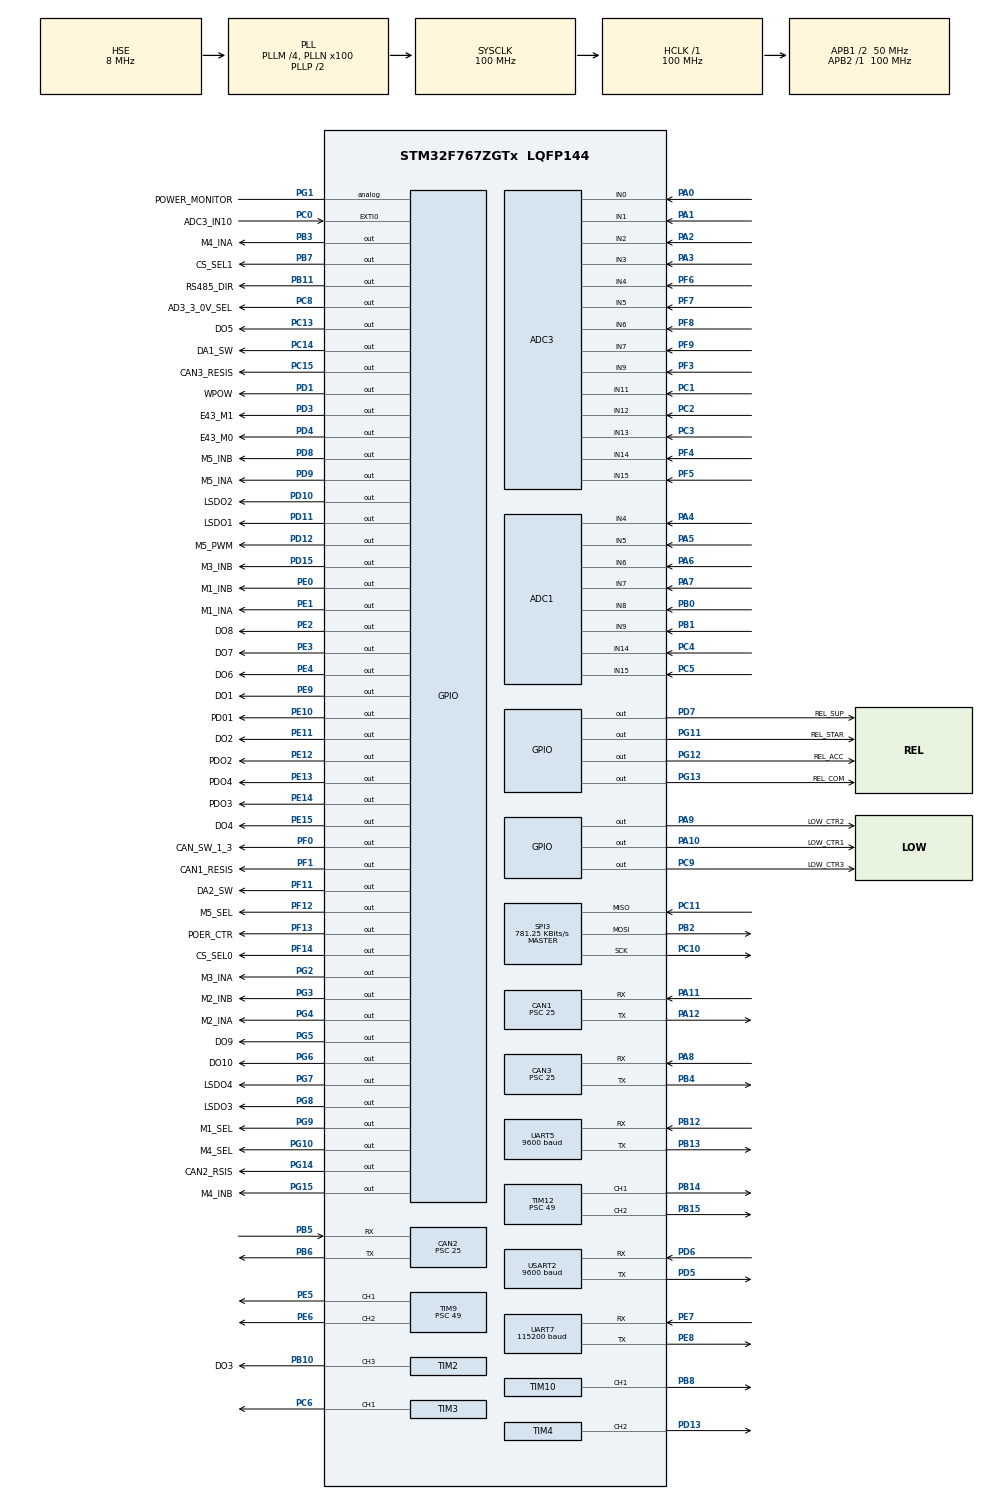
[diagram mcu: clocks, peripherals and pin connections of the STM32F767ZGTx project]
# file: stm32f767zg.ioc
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ADC1.Channel-0\#ChannelRegularConversion=ADC_CHANNEL_4
ADC1.Channel-1\#ChannelRegularConversion=ADC_CHANNEL_5
ADC1.Channel-10\#ChannelRegularConversion=ADC_CHANNEL_14
ADC1.Channel-11\#ChannelRegularConversion=ADC_CHANNEL_15
ADC1.Channel-12\#ChannelRegularConversion=ADC_CHANNEL_TEMPSENSOR
ADC1.Channel-13\#ChannelRegularConversion=ADC_CHANNEL_VREFINT
ADC1.Channel-6\#ChannelRegularConversion=ADC_CHANNEL_6
ADC1.Channel-7\#ChannelRegularConversion=ADC_CHANNEL_7
ADC1.Channel-8\#ChannelRegularConversion=ADC_CHANNEL_8
ADC1.Channel-9\#ChannelRegularConversion=ADC_CHANNEL_9
ADC1.ContinuousConvMode=ENABLE
ADC1.DMAContinuousRequests=ENABLE
ADC1.EOCSelection=ADC_EOC_SEQ_CONV
ADC1.InjNumberOfConversion=0
ADC1.NbrOfConversion=10
ADC1.NbrOfConversionFlag=1
ADC1.Rank-0\#ChannelRegularConversion=1
ADC1.Rank-1\#ChannelRegularConversion=2
ADC1.Rank-10\#ChannelRegularConversion=7
ADC1.Rank-11\#ChannelRegularConversion=8
ADC1.Rank-12\#ChannelRegularConversion=9
ADC1.Rank-13\#ChannelRegularConversion=10
ADC1.Rank-6\#ChannelRegularConversion=3
ADC1.Rank-7\#ChannelRegularConversion=4
ADC1.Rank-8\#ChannelRegularConversion=5
ADC1.Rank-9\#ChannelRegularConversion=6
ADC1.SamplingTime-0\#ChannelRegularConversion=ADC_SAMPLETIME_56CYCLES
ADC1.SamplingTime-1\#ChannelRegularConversion=ADC_SAMPLETIME_56CYCLES
ADC1.SamplingTime-10\#ChannelRegularConversion=ADC_SAMPLETIME_56CYCLES
ADC1.SamplingTime-11\#ChannelRegularConversion=ADC_SAMPLETIME_56CYCLES
ADC1.SamplingTime-12\#ChannelRegularConversion=ADC_SAMPLETIME_112CYCLES
ADC1.SamplingTime-13\#ChannelRegularConversion=ADC_SAMPLETIME_3CYCLES
ADC1.SamplingTime-6\#ChannelRegularConversion=ADC_SAMPLETIME_56CYCLES
ADC1.SamplingTime-7\#ChannelRegularConversion=ADC_SAMPLETIME_56CYCLES
ADC1.SamplingTime-8\#ChannelRegularConversion=ADC_SAMPLETIME_56CYCLES
ADC1.SamplingTime-9\#ChannelRegularConversion=ADC_SAMPLETIME_56CYCLES
ADC1.ScanConvMode=ADC_SCAN_ENABLE
ADC1.master=1
ADC3.Channel-0\#ChannelRegularConversion=ADC_CHANNEL_0
ADC3.Channel-1\#ChannelRegularConversion=ADC_CHANNEL_1
ADC3.Channel-10\#ChannelRegularConversion=ADC_CHANNEL_12
ADC3.Channel-11\#ChannelRegularConversion=ADC_CHANNEL_13
ADC3.Channel-12\#ChannelRegularConversion=ADC_CHANNEL_14
ADC3.Channel-13\#ChannelRegularConversion=ADC_CHANNEL_15
ADC3.Channel-14\#ChannelRegularConversion=ADC_CHANNEL_7
ADC3.Channel-2\#ChannelRegularConversion=ADC_CHANNEL_2
ADC3.Channel-3\#ChannelRegularConversion=ADC_CHANNEL_3
ADC3.Channel-4\#ChannelRegularConversion=ADC_CHANNEL_4
ADC3.Channel-5\#ChannelRegularConversion=ADC_CHANNEL_5
ADC3.Channel-6\#ChannelRegularConversion=ADC_CHANNEL_6
ADC3.Channel-7\#ChannelRegularConversion=ADC_CHANNEL_9
ADC3.Channel-8\#ChannelRegularConversion=ADC_CHANNEL_9
ADC3.Channel-9\#ChannelRegularConversion=ADC_CHANNEL_11
ADC3.ContinuousConvMode=ENABLE
ADC3.DMAContinuousRequests=ENABLE
ADC3.NbrOfConversion=15
ADC3.NbrOfConversionFlag=1
ADC3.Rank-0\#ChannelRegularConversion=1
ADC3.Rank-1\#ChannelRegularConversion=2
ADC3.Rank-10\#ChannelRegularConversion=11
ADC3.Rank-11\#ChannelRegularConversion=12
ADC3.Rank-12\#ChannelRegularConversion=13
ADC3.Rank-13\#ChannelRegularConversion=14
ADC3.Rank-14\#ChannelRegularConversion=15
ADC3.Rank-2\#ChannelRegularConversion=3
ADC3.Rank-3\#ChannelRegularConversion=4
ADC3.Rank-4\#ChannelRegularConversion=5
ADC3.Rank-5\#ChannelRegularConversion=6
ADC3.Rank-6\#ChannelRegularConversion=7
ADC3.Rank-7\#ChannelRegularConversion=8
ADC3.Rank-8\#ChannelRegularConversion=9
ADC3.Rank-9\#ChannelRegularConversion=10
ADC3.SamplingTime-0\#ChannelRegularConversion=ADC_SAMPLETIME_56CYCLES
ADC3.SamplingTime-1\#ChannelRegularConversion=ADC_SAMPLETIME_56CYCLES
ADC3.SamplingTime-10\#ChannelRegularConversion=ADC_SAMPLETIME_56CYCLES
ADC3.SamplingTime-11\#ChannelRegularConversion=ADC_SAMPLETIME_56CYCLES
ADC3.SamplingTime-12\#ChannelRegularConversion=ADC_SAMPLETIME_56CYCLES
ADC3.SamplingTime-13\#ChannelRegularConversion=ADC_SAMPLETIME_56CYCLES
ADC3.SamplingTime-14\#ChannelRegularConversion=ADC_SAMPLETIME_56CYCLES
ADC3.SamplingTime-2\#ChannelRegularConversion=ADC_SAMPLETIME_56CYCLES
ADC3.SamplingTime-3\#ChannelRegularConversion=ADC_SAMPLETIME_56CYCLES
ADC3.SamplingTime-4\#ChannelRegularConversion=ADC_SAMPLETIME_56CYCLES
ADC3.SamplingTime-5\#ChannelRegularConversion=ADC_SAMPLETIME_56CYCLES
ADC3.SamplingTime-6\#ChannelRegularConversion=ADC_SAMPLETIME_56CYCLES
ADC3.SamplingTime-7\#ChannelRegularConversion=ADC_SAMPLETIME_56CYCLES
ADC3.SamplingTime-8\#ChannelRegularConversion=ADC_SAMPLETIME_15CYCLES
ADC3.SamplingTime-9\#ChannelRegularConversion=ADC_SAMPLETIME_56CYCLES
ADC3.ScanConvMode=ADC_SCAN_ENABLE
CAN1.ABOM=DISABLE
CAN1.AWUM=DISABLE
CAN1.BS1=CAN_BS1_4TQ
CAN1.BS2=CAN_BS2_3TQ
CAN1.CalculateBaudRate=250000
CAN1.CalculateTimeBit=4000
CAN1.CalculateTimeQuantum=500.0
CAN1.Mode=CAN_MODE_NORMAL
CAN1.NART=DISABLE
CAN1.Prescaler=25
CAN1.RFLM=DISABLE
CAN1.SJW=CAN_SJW_1TQ
CAN1.TTCM=DISABLE
CAN1.TXFP=DISABLE
CAN2.ABOM=DISABLE
CAN2.AWUM=DISABLE
CAN2.BS1=CAN_BS1_4TQ
CAN2.BS2=CAN_BS2_3TQ
CAN2.CalculateBaudRate=250000
CAN2.CalculateTimeBit=4000
CAN2.CalculateTimeQuantum=500.0
CAN2.Mode=CAN_MODE_NORMAL
CAN2.NART=DISABLE
CAN2.Prescaler=25
CAN2.RFLM=DISABLE
CAN2.SJW=CAN_SJW_1TQ
CAN2.TTCM=DISABLE
CAN2.TXFP=DISABLE
CAN3.ABOM=DISABLE
CAN3.AWUM=DISABLE
CAN3.BS1=CAN_BS1_4TQ
CAN3.BS2=CAN_BS2_3TQ
CAN3.CalculateBaudRate=250000
CAN3.CalculateTimeBit=4000
CAN3.CalculateTimeQuantum=500.0
CAN3.Mode=CAN_MODE_NORMAL
CAN3.NART=DISABLE
CAN3.Prescaler=25
CAN3.RFLM=DISABLE
CAN3.SJW=CAN_SJW_1TQ
CAN3.TTCM=DISABLE
CAN3.TXFP=DISABLE
CORTEX_M7.ART_ACCLERATOR_ENABLE=0
CORTEX_M7.CPU_DCache=Enabled
CORTEX_M7.CPU_ICache=Enabled
CORTEX_M7.FlashInterface=AXI_Enabled
CORTEX_M7.MPU_Control=__NULL
CORTEX_M7.PREFETCH_ENABLE=0
Dma.ADC1.0.Direction=DMA_PERIPH_TO_MEMORY
Dma.ADC1.0.FIFOMode=DMA_FIFOMODE_DISABLE
Dma.ADC1.0.Instance=DMA2_Stream0
Dma.ADC1.0.MemDataAlignment=DMA_MDATAALIGN_WORD
Dma.ADC1.0.MemInc=DMA_MINC_ENABLE
Dma.ADC1.0.Mode=DMA_CIRCULAR
Dma.ADC1.0.PeriphDataAlignment=DMA_PDATAALIGN_WORD
Dma.ADC1.0.PeriphInc=DMA_PINC_DISABLE
Dma.ADC1.0.Priority=DMA_PRIORITY_LOW
Dma.ADC3.1.Direction=DMA_PERIPH_TO_MEMORY
Dma.ADC3.1.FIFOMode=DMA_FIFOMODE_DISABLE
Dma.ADC3.1.Instance=DMA2_Stream1
Dma.ADC3.1.MemDataAlignment=DMA_MDATAALIGN_WORD
Dma.ADC3.1.MemInc=DMA_MINC_ENABLE
Dma.ADC3.1.Mode=DMA_CIRCULAR
Dma.ADC3.1.PeriphDataAlignment=DMA_PDATAALIGN_WORD
Dma.ADC3.1.PeriphInc=DMA_PINC_DISABLE
Dma.ADC3.1.Priority=DMA_PRIORITY_LOW
Dma.Request0=ADC1
Dma.Request1=ADC3
FREERTOS.CountingSemaphores01=myCountingSemMoter1,1,Dynamic,NULL;myCountingSemMoter2,1,Dynamic,NULL;myCountingSemMoter3,1,Dynamic,NULL;myCountingSemMoter4,1,Dynamic,NULL;myCountingSemMoter5,1,Dynamic,NULL;myCountingSemEngine,1,Dynamic,NULL;myCountingSemDO,1,Dynamic,NULL;myCountingSemPend1,1,Dynamic,NULL;myCountingSemElecAccelerator,1,Dynamic,NULL;myCountingSemTube,1,Dynamic,NULL;myCountingSemTurn,1,Dynamic,NULL;myCountingSemAutoTurn,1,Dynamic,NULL
FREERTOS.HEAP_NUMBER=4
FREERTOS.INCLUDE_eTaskGetState=1
FREERTOS.INCLUDE_pcTaskGetTaskName=0
FREERTOS.INCLUDE_uxTaskGetStackHighWaterMark=1
FREERTOS.INCLUDE_uxTaskGetStackHighWaterMark2=0
FREERTOS.INCLUDE_uxTaskPriorityGet=1
FREERTOS.INCLUDE_vTaskCleanUpResources=0
FREERTOS.INCLUDE_vTaskDelay=1
FREERTOS.INCLUDE_vTaskDelayUntil=1
FREERTOS.INCLUDE_vTaskDelete=1
FREERTOS.INCLUDE_vTaskPrioritySet=1
FREERTOS.INCLUDE_vTaskSuspend=1
FREERTOS.INCLUDE_xEventGroupSetBitFromISR=0
FREERTOS.INCLUDE_xQueueGetMutexHolder=1
FREERTOS.INCLUDE_xSemaphoreGetMutexHolder=0
FREERTOS.INCLUDE_xTaskAbortDelay=0
FREERTOS.INCLUDE_xTaskGetCurrentTaskHandle=0
FREERTOS.INCLUDE_xTaskGetHandle=0
FREERTOS.INCLUDE_xTaskGetSchedulerState=1
FREERTOS.INCLUDE_xTaskResumeFromISR=1
FREERTOS.INCLUDE_xTimerPendFunctionCall=1
FREERTOS.Queues01=myQueueCan2Rev,5,12,1,Dynamic,NULL,NULL;myQueueCan1Rev,5,12,1,Dynamic,NULL,NULL;myQueueCan3Rev,5,12,1,Dynamic,NULL,NULL;myQueueUart7Rec,2,30,1,Dynamic,NULL,NULL;myQueueUart2Spi3Rec,6,10,1,Dynamic,NULL,NULL
FREERTOS.Tasks01=defaultTask,8,128,StartDefaultTask,Default,NULL,Dynamic,NULL,NULL;myTask02,47,128,StartTask02,Default,NULL,Dynamic,NULL,NULL;myTask03,46,128,StartTask03,Default,NULL,Dynamic,NULL,NULL;myTask04,45,128,StartTask04,Default,NULL,Dynamic,NULL,NULL;myTask05,44,128,StartTask05,Default,NULL,Dynamic,NULL,NULL;myTask06,43,128,StartTask06,Default,NULL,Dynamic,NULL,NULL;myTask07,42,128,StartTask07,Default,NULL,Dynamic,NULL,NULL;myTask08,31,128,StartTask08,Default,NULL,Dynamic,NULL,NULL;myTask09,30,128,StartTask09,Default,NULL,Dynamic,NULL,NULL;myTask10,29,128,StartTask10,Default,NULL,Dynamic,NULL,NULL;myTask11,28,128,StartTask11,Default,NULL,Dynamic,NULL,NULL;myTask12,27,128,StartTask12,Default,NULL,Dynamic,NULL,NULL;myTask13,26,128,StartTask13,Default,NULL,Dynamic,NULL,NULL;myTask14,25,128,StartTask14,Default,NULL,Dynamic,NULL,NULL;myTask15,24,128,StartTask15,Default,NULL,Dynamic,NULL,NULL;myTask20,9,128,StartTask20,Default,NULL,Dynamic,NULL,NULL;myTask16,23,128,StartTask16,Default,NULL,Dynamic,NULL,NULL;myTask17,22,128,StartTask17,Default,NULL,Dynamic,NULL,NULL;myTask18,21,128,StartTask18,Default,NULL,Dynamic,NULL,NULL;myTask19,20,128,StartTask19,Default,NULL,Dynamic,NULL,NULL;myTask21,41,128,StartTask21,Default,NULL,Dynamic,NULL,NULL
FREERTOS.Timers01=myTimerCanSend,CallbackCanSend,osTimerPeriodic,Default,NULL,Dynamic,NULL;myTimerDO,CallbackDO,osTimerPeriodic,Default,NULL,Dynamic,NULL;myTimerCounter,CallbackCounter,osTimerPeriodic,Default,NULL,Dynamic,NULL
FREERTOS.configCHECK_FOR_STACK_OVERFLOW=0
FREERTOS.configENABLE_BACKWARD_COMPATIBILITY=1
FREERTOS.configENABLE_FPU=0
FREERTOS.configGENERATE_RUN_TIME_STATS=0
FREERTOS.configIDLE_SHOULD_YIELD=1
FREERTOS.configLIBRARY_LOWEST_INTERRUPT_PRIORITY=15
FREERTOS.configLIBRARY_MAX_SYSCALL_INTERRUPT_PRIORITY=5
FREERTOS.configMAX_CO_ROUTINE_PRIORITIES=2
FREERTOS.configMAX_TASK_NAME_LEN=16
FREERTOS.configMINIMAL_STACK_SIZE=128
FREERTOS.configQUEUE_REGISTRY_SIZE=8
FREERTOS.configRECORD_STACK_HIGH_ADDRESS=0
FREERTOS.configTICK_RATE_HZ=1000
FREERTOS.configTIMER_QUEUE_LENGTH=10
FREERTOS.configTIMER_TASK_PRIORITY=2
FREERTOS.configTIMER_TASK_STACK_DEPTH=256
FREERTOS.configTOTAL_HEAP_SIZE=15360
FREERTOS.configUSE_APPLICATION_TASK_TAG=0
FREERTOS.configUSE_COUNTING_SEMAPHORES=1
FREERTOS.configUSE_CO_ROUTINES=0
FREERTOS.configUSE_DAEMON_TASK_STARTUP_HOOK=0
FREERTOS.configUSE_IDLE_HOOK=0
FREERTOS.configUSE_MALLOC_FAILED_HOOK=0
FREERTOS.configUSE_MUTEXES=1
FREERTOS.configUSE_NEWLIB_REENTRANT=0
FREERTOS.configUSE_POSIX_ERRNO=0
FREERTOS.configUSE_PREEMPTION=1
FREERTOS.configUSE_RECURSIVE_MUTEXES=1
FREERTOS.configUSE_STATS_FORMATTING_FUNCTIONS=0
FREERTOS.configUSE_TASK_NOTIFICATIONS=1
FREERTOS.configUSE_TICKLESS_IDLE=0
FREERTOS.configUSE_TICK_HOOK=0
FREERTOS.configUSE_TRACE_FACILITY=1
FREERTOS.copyHeapFile=1
IWDG.Prescaler=IWDG_PRESCALER_32
IWDG.Reload=2000
IWDG.Window=2000
Mcu.Family=STM32F7
Mcu.Name=STM32F767ZGTx
Mcu.Package=LQFP144
NVIC.CAN1_RX0_IRQn=true\:6\:0\:true\:false\:true\:true\:true\:true\:true
NVIC.CAN2_RX1_IRQn=true\:7\:0\:true\:false\:true\:true\:true\:true\:true
NVIC.CAN3_RX0_IRQn=true\:8\:0\:true\:false\:true\:true\:true\:true\:true
NVIC.DMA2_Stream0_IRQn=true\:5\:0\:false\:false\:true\:true\:false\:true\:true
NVIC.DMA2_Stream1_IRQn=true\:5\:0\:false\:false\:true\:true\:false\:true\:true
NVIC.EXTI0_IRQn=true\:5\:0\:false\:false\:true\:true\:true\:true\:true
NVIC.PriorityGroup=NVIC_PRIORITYGROUP_4
NVIC.TIM8_TRG_COM_TIM14_IRQn=true\:0\:0\:false\:false\:true\:false\:false\:true\:true
NVIC.TimeBase=TIM8_TRG_COM_TIM14_IRQn
NVIC.TimeBaseIP=TIM14
NVIC.UART5_IRQn=true\:11\:0\:true\:false\:true\:true\:true\:true\:true
NVIC.UART7_IRQn=true\:15\:0\:true\:false\:true\:true\:true\:true\:true
NVIC.USART2_IRQn=true\:10\:0\:true\:false\:true\:true\:true\:true\:true
PA0/WKUP.Signal=ADCx_IN0
PA1.Signal=ADCx_IN1
PA10.GPIO_Label=LOW_CTR1
PA10.Signal=GPIO_Output
PA11.Mode=CAN_Activate
PA11.Signal=CAN1_RX
PA12.Mode=CAN_Activate
PA12.Signal=CAN1_TX
PA13.Mode=Serial_Wire
PA13.Signal=SYS_JTMS-SWDIO
PA14.Mode=Serial_Wire
PA14.Signal=SYS_JTCK-SWCLK
PA2.Signal=ADCx_IN2
PA3.Signal=ADCx_IN3
PA4.Signal=ADCx_IN4
PA5.Signal=ADCx_IN5
PA6.Signal=ADCx_IN6
PA7.Signal=ADCx_IN7
PA8.Mode=CAN_Activate
PA8.Signal=CAN3_RX
PA9.GPIO_Label=LOW_CTR2
PA9.Signal=GPIO_Output
PB0.Signal=ADCx_IN8
PB1.Signal=ADCx_IN9
PB10.GPIO_Label=DO3
PB10.Signal=S_TIM2_CH3
PB11.GPIO_Label=RS485_DIR
PB11.Signal=GPIO_Output
PB12.Mode=Asynchronous
PB12.Signal=UART5_RX
PB13.Mode=Asynchronous
PB13.Signal=UART5_TX
PB14.Signal=S_TIM12_CH1
PB15.Signal=S_TIM12_CH2
PB2.Mode=Full_Duplex_Master
PB2.Signal=SPI3_MOSI
PB3.GPIO_Label=M4_INA
PB3.Signal=GPIO_Output
PB4.Mode=CAN_Activate
PB4.Signal=CAN3_TX
PB5.Mode=CAN_Activate
PB5.Signal=CAN2_RX
PB6.Mode=CAN_Activate
PB6.Signal=CAN2_TX
PB7.GPIO_Label=CS_SEL1
PB7.Signal=GPIO_Output
PB8.Signal=S_TIM10_CH1
PC0.GPIO_Label=ADC3_IN10
PC0.Signal=GPXTI0
PC1.Signal=ADCx_IN11
PC10.Mode=Full_Duplex_Master
PC10.Signal=SPI3_SCK
PC11.Mode=Full_Duplex_Master
PC11.Signal=SPI3_MISO
PC13.GPIO_Label=DO5
PC13.Signal=GPIO_Output
PC14/OSC32_IN.GPIO_Label=DA1_SW
PC14/OSC32_IN.Signal=GPIO_Output
PC15/OSC32_OUT.GPIO_Label=CAN3_RESIS
PC15/OSC32_OUT.Signal=GPIO_Output
PC2.Signal=ADCx_IN12
PC3.Signal=ADCx_IN13
PC4.Signal=ADCx_IN14
PC5.Signal=ADCx_IN15
PC6.Signal=S_TIM3_CH1
PC8.GPIO_Label=AD3_3_0V_SEL
PC8.Signal=GPIO_Output
PC9.GPIO_Label=LOW_CTR3
PC9.Signal=GPIO_Output
PD1.GPIO_Label=WPOW
PD1.Signal=GPIO_Output
PD10.GPIO_Label=LSDO2
PD10.Signal=GPIO_Output
PD11.GPIO_Label=LSDO1
PD11.Signal=GPIO_Output
PD12.GPIO_Label=M5_PWM
PD12.Signal=GPIO_Output
PD13.Signal=S_TIM4_CH2
PD15.GPIO_Label=M3_INB
PD15.Signal=GPIO_Output
PD3.GPIO_Label=E43_M1
PD3.Signal=GPIO_Output
PD4.GPIO_Label=E43_M0
PD4.Signal=GPIO_Output
PD5.Mode=Asynchronous
PD5.Signal=USART2_TX
PD6.Mode=Asynchronous
PD6.Signal=USART2_RX
PD7.GPIO_Label=REL_SUP
PD7.Signal=GPIO_Output
PD8.GPIO_Label=M5_INB
PD8.Signal=GPIO_Output
PD9.GPIO_Label=M5_INA
PD9.Signal=GPIO_Output
PE0.GPIO_Label=M1_INB
PE0.Signal=GPIO_Output
PE1.GPIO_Label=M1_INA
PE1.Signal=GPIO_Output
PE10.GPIO_Label=PD01
PE10.Signal=GPIO_Output
PE11.GPIO_Label=DO2
PE11.Signal=GPIO_Output
PE12.GPIO_Label=PDO2
PE12.Signal=GPIO_Output
PE13.GPIO_Label=PDO4
PE13.Signal=GPIO_Output
PE14.GPIO_Label=PDO3
PE14.Signal=GPIO_Output
PE15.GPIO_Label=DO4
PE15.Signal=GPIO_Output
PE2.GPIO_Label=DO8
PE2.Signal=GPIO_Output
PE3.GPIO_Label=DO7
PE3.Signal=GPIO_Output
PE4.GPIO_Label=DO6
PE4.Signal=GPIO_Output
PE5.Signal=S_TIM9_CH1
PE6.Signal=S_TIM9_CH2
PE7.Mode=Asynchronous
PE7.Signal=UART7_RX
PE8.Mode=Asynchronous
PE8.Signal=UART7_TX
PE9.GPIO_Label=DO1
PE9.Signal=GPIO_Output
PF0.GPIO_Label=CAN_SW_1_3
PF0.Signal=GPIO_Output
PF1.GPIO_Label=CAN1_RESIS
PF1.Signal=GPIO_Output
PF11.GPIO_Label=DA2_SW
PF11.Signal=GPIO_Output
PF12.GPIO_Label=M5_SEL
PF12.Signal=GPIO_Output
PF13.GPIO_Label=POER_CTR
PF13.Signal=GPIO_Output
PF14.GPIO_Label=CS_SEL0
PF14.Signal=GPIO_Output
PF3.Mode=IN9
PF3.Signal=ADC3_IN9
PF4.Mode=IN14
PF4.Signal=ADC3_IN14
PF5.Mode=IN15
PF5.Signal=ADC3_IN15
PF6.Mode=IN4
PF6.Signal=ADC3_IN4
PF7.Mode=IN5
PF7.Signal=ADC3_IN5
PF8.Mode=IN6
PF8.Signal=ADC3_IN6
PF9.Mode=IN7
PF9.Signal=ADC3_IN7
PG1.GPIO_Label=POWER_MONITOR
PG1.Signal=GPIO_Analog
PG10.GPIO_Label=M4_SEL
PG10.Signal=GPIO_Output
PG11.GPIO_Label=REL_STAR
PG11.Signal=GPIO_Output
PG12.GPIO_Label=REL_ACC
PG12.Signal=GPIO_Output
PG13.GPIO_Label=REL_COM
PG13.Signal=GPIO_Output
PG14.GPIO_Label=CAN2_RSIS
PG14.Signal=GPIO_Output
PG15.GPIO_Label=M4_INB
PG15.Signal=GPIO_Output
PG2.GPIO_Label=M3_INA
PG2.Signal=GPIO_Output
PG3.GPIO_Label=M2_INB
PG3.Signal=GPIO_Output
PG4.GPIO_Label=M2_INA
PG4.Signal=GPIO_Output
PG5.GPIO_Label=DO9
PG5.Signal=GPIO_Output
PG6.GPIO_Label=DO10
PG6.Signal=GPIO_Output
PG7.GPIO_Label=LSDO4
PG7.Signal=GPIO_Output
PG8.GPIO_Label=LSDO3
PG8.Signal=GPIO_Output
PG9.GPIO_Label=M1_SEL
PG9.Signal=GPIO_Output
PH0/OSC_IN.Mode=HSE-External-Oscillator
PH0/OSC_IN.Signal=RCC_OSC_IN
PH1/OSC_OUT.Mode=HSE-External-Oscillator
PH1/OSC_OUT.Signal=RCC_OSC_OUT
ProjectManager.HeapSize=0x5000
ProjectManager.StackSize=0x8000
ProjectManager.TargetToolchain=MDK-ARM V5.27
RCC.AHBFreq_Value=100000000
RCC.APB1CLKDivider=RCC_HCLK_DIV2
RCC.APB1Freq_Value=50000000
RCC.APB1TimFreq_Value=100000000
RCC.APB2Freq_Value=100000000
RCC.APB2TimFreq_Value=100000000
RCC.CortexFreq_Value=100000000
RCC.FLatency=FLASH_LATENCY_3
RCC.HCLKFreq_Value=100000000
RCC.HSE_VALUE=8000000
RCC.HSI_VALUE=16000000
RCC.LSE_VALUE=32768
RCC.PLLM=4
RCC.PLLN=100
RCC.PLLSourceVirtual=RCC_PLLSOURCE_HSE
RCC.PWREXT_OverDrive=PWREXT_OverDrive_ACTIVATED
RCC.SYSCLKFreq_VALUE=100000000
RCC.SYSCLKSource=RCC_SYSCLKSOURCE_PLLCLK
RCC.USBFreq_Value=100000000
RCC.VCOOutputFreq_Value=200000000
SH.ADCx_IN0.0=ADC3_IN0,IN0
SH.ADCx_IN1.0=ADC3_IN1,IN1
SH.ADCx_IN11.0=ADC3_IN11,IN11
SH.ADCx_IN12.0=ADC3_IN12,IN12
SH.ADCx_IN13.0=ADC3_IN13,IN13
SH.ADCx_IN14.0=ADC1_IN14,IN14
SH.ADCx_IN15.0=ADC1_IN15,IN15
SH.ADCx_IN2.0=ADC3_IN2,IN2
SH.ADCx_IN3.0=ADC3_IN3,IN3
SH.ADCx_IN4.0=ADC1_IN4,IN4
SH.ADCx_IN5.0=ADC1_IN5,IN5
SH.ADCx_IN6.0=ADC1_IN6,IN6
SH.ADCx_IN7.0=ADC1_IN7,IN7
SH.ADCx_IN8.0=ADC1_IN8,IN8
SH.ADCx_IN9.0=ADC1_IN9,IN9
SH.S_TIM10_CH1.0=TIM10_CH1,PWM Generation1 CH1
SH.S_TIM12_CH1.0=TIM12_CH1,PWM Generation1 CH1
SH.S_TIM12_CH2.0=TIM12_CH2,PWM Generation2 CH2
SH.S_TIM2_CH3.0=TIM2_CH3,PWM Generation3 CH3
SH.S_TIM3_CH1.0=TIM3_CH1,PWM Generation1 CH1
SH.S_TIM4_CH2.0=TIM4_CH2,PWM Generation2 CH2
SH.S_TIM9_CH1.0=TIM9_CH1,PWM Generation1 CH1
SH.S_TIM9_CH2.0=TIM9_CH2,PWM Generation2 CH2
SPI3.BaudRatePrescaler=SPI_BAUDRATEPRESCALER_64
SPI3.CalculateBaudRate=781.25 KBits/s
SPI3.DataSize=SPI_DATASIZE_10BIT
SPI3.Direction=SPI_DIRECTION_2LINES
SPI3.Mode=SPI_MODE_MASTER
SPI3.VirtualType=VM_MASTER
TIM10.AutoReloadPreload=TIM_AUTORELOAD_PRELOAD_ENABLE
TIM10.Channel=TIM_CHANNEL_1
TIM10.ClockDivision=TIM_CLOCKDIVISION_DIV2
TIM10.Period=499
TIM10.Prescaler=49
TIM12.AutoReloadPreload=TIM_AUTORELOAD_PRELOAD_ENABLE
TIM12.Channel-PWM\ Generation1\ CH1=TIM_CHANNEL_1
TIM12.Channel-PWM\ Generation2\ CH2=TIM_CHANNEL_2
TIM12.ClockDivision=TIM_CLOCKDIVISION_DIV2
TIM12.Period=499
TIM12.Prescaler=49
TIM12.Pulse-PWM\ Generation1\ CH1=250
TIM12.Pulse-PWM\ Generation2\ CH2=250
TIM2.AutoReloadPreload=TIM_AUTORELOAD_PRELOAD_ENABLE
TIM2.Channel-PWM\ Generation3\ CH3=TIM_CHANNEL_3
TIM2.ClockDivision=TIM_CLOCKDIVISION_DIV2
TIM2.Period=499
TIM2.Prescaler=49
TIM2.TIM_MasterOutputTrigger=TIM_TRGO_RESET
TIM3.AutoReloadPreload=TIM_AUTORELOAD_PRELOAD_ENABLE
TIM3.Channel-PWM\ Generation1\ CH1=TIM_CHANNEL_1
TIM3.ClockDivision=TIM_CLOCKDIVISION_DIV2
TIM3.Period=499
TIM3.Prescaler=49
TIM3.Pulse-PWM\ Generation1\ CH1=250
TIM4.AutoReloadPreload=TIM_AUTORELOAD_PRELOAD_ENABLE
TIM4.Channel-PWM\ Generation2\ CH2=TIM_CHANNEL_2
TIM4.ClockDivision=TIM_CLOCKDIVISION_DIV2
TIM4.Period=499
TIM4.Prescaler=49
TIM4.Pulse-PWM\ Generation2\ CH2=250
TIM5.AutoReloadPreload=TIM_AUTORELOAD_PRELOAD_ENABLE
TIM5.Period=999
TIM5.Prescaler=49
TIM9.Channel-PWM\ Generation1\ CH1=TIM_CHANNEL_1
TIM9.Channel-PWM\ Generation2\ CH2=TIM_CHANNEL_2
TIM9.ClockDivision=TIM_CLOCKDIVISION_DIV2
TIM9.Period=499
TIM9.Prescaler=49
TIM9.Pulse-PWM\ Generation1\ CH1=250
TIM9.Pulse-PWM\ Generation2\ CH2=250
UART5.AutoBaudRateEnableParam=UART_ADVFEATURE_AUTOBAUDRATE_DISABLE
UART5.BaudRate=9600
UART5.DMADisableonRxErrorParam=UART_ADVFEATURE_DMA_ENABLEONRXERROR
UART5.DataInvertParam=UART_ADVFEATURE_DATAINV_DISABLE
UART5.MSBFirstParam=UART_ADVFEATURE_MSBFIRST_DISABLE
UART5.Mode=MODE_TX_RX
UART5.OneBitSampling=UART_ONE_BIT_SAMPLE_DISABLE
UART5.OverSampling=UART_OVERSAMPLING_16
UART5.OverrunDisableParam=UART_ADVFEATURE_OVERRUN_ENABLE
UART5.Parity=PARITY_NONE
UART5.RxPinLevelInvertParam=UART_ADVFEATURE_RXINV_DISABLE
UART5.StopBits=UART_STOPBITS_1
UART5.SwapParam=UART_ADVFEATURE_SWAP_DISABLE
UART5.TxPinLevelInvertParam=UART_ADVFEATURE_TXINV_DISABLE
UART5.WordLength=WORDLENGTH_8B
UART7.AutoBaudRateEnableParam=UART_ADVFEATURE_AUTOBAUDRATE_DISABLE
UART7.BaudRate=115200
UART7.DMADisableonRxErrorParam=UART_ADVFEATURE_DMA_ENABLEONRXERROR
UART7.DataInvertParam=UART_ADVFEATURE_DATAINV_DISABLE
UART7.MSBFirstParam=UART_ADVFEATURE_MSBFIRST_DISABLE
UART7.Mode=MODE_TX_RX
UART7.OneBitSampling=UART_ONE_BIT_SAMPLE_DISABLE
UART7.OverSampling=UART_OVERSAMPLING_16
UART7.OverrunDisableParam=UART_ADVFEATURE_OVERRUN_ENABLE
UART7.Parity=PARITY_NONE
UART7.RxPinLevelInvertParam=UART_ADVFEATURE_RXINV_DISABLE
UART7.StopBits=UART_STOPBITS_1
UART7.SwapParam=UART_ADVFEATURE_SWAP_DISABLE
UART7.TxPinLevelInvertParam=UART_ADVFEATURE_TXINV_DISABLE
UART7.WordLength=WORDLENGTH_8B
USART2.BaudRate=9600
USART2.VirtualMode-Asynchronous=VM_ASYNC
VP_ADC1_TempSens_Input.Mode=IN-TempSens
VP_ADC1_Vref_Input.Mode=IN-Vrefint
VP_FREERTOS_VS_CMSIS_V2.Mode=CMSIS_V2
VP_IWDG_VS_IWDG.Mode=IWDG_Activate
VP_SYS_VS_tim14.Mode=TIM14
VP_TIM10_VS_ClockSourceINT.Mode=Enable_Timer
VP_TIM12_VS_ClockSourceINT.Mode=Internal
VP_TIM2_VS_ClockSourceINT.Mode=Internal
VP_TIM3_VS_ClockSourceINT.Mode=Internal
VP_TIM4_VS_ClockSourceINT.Mode=Internal
VP_TIM5_VS_ClockSourceINT.Mode=Internal
VP_TIM9_VS_ClockSourceINT.Mode=Internal
board=custom

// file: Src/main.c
/* USER CODE BEGIN Header */
/**
  ******************************************************************************
  * @file           : main.c
  * @brief          : Main program body
  ******************************************************************************
  * @attention
  *
  * <h2><center>&copy; Copyright (c) 2020 STMicroelectronics.
  * All rights reserved.</center></h2>
  *
  * This software component is licensed by ST under Ultimate Liberty license
  * SLA0044, the "License"; You may not use this file except in compliance with
  * the License. You may obtain a copy of the License at:
  *                             www.st.com/SLA0044
  *
  ******************************************************************************
  */
/* USER CODE END Header */
#include "main.h"
#include "cmsis_os.h"
#include "adc.h"
#include "can.h"
#include "dma.h"
#include "iwdg.h"
#include "spi.h"
#include "tim.h"
#include "usart.h"
#include "gpio.h"

/* USER CODE BEGIN Includes */
#include "USER_FLASH.h"
#include "USER_PRO.h"
#include "USER_SET.h"
#include "USER_WIRE_LESS.h"
#include "USER_PPM.h"
#include "LSCanUpgrade.h"
/* USER CODE END Includes */

void SystemClock_Config(void);
void MX_FREERTOS_Init(void);

int main(void)
{

  /* Enable I-Cache---------------------------------------------------------*/
  SCB_EnableICache();

  /* Enable D-Cache---------------------------------------------------------*/
  SCB_EnableDCache();

  /* MCU Configuration--------------------------------------------------------*/

  /* Reset of all peripherals, Initializes the Flash interface and the Systick. */
  HAL_Init();

  /* USER CODE BEGIN Init */
//	user_can_init( );
//		SCB->CACR|=1<<2;   //强制D-Cache透写,如不开启,实际使用中可能遇到各种问题
  /* USER CODE END Init */

  /* Configure the system clock */
  SystemClock_Config();

  /* Initialize all configured peripherals */
  MX_GPIO_Init();
  MX_DMA_Init();
  MX_CAN1_Init();
  MX_CAN2_Init();
  MX_CAN3_Init();
  MX_SPI3_Init();
  MX_UART5_Init();
  MX_UART7_Init();
  MX_USART2_UART_Init();
  MX_ADC1_Init();
  MX_TIM2_Init();
  MX_TIM12_Init();
  MX_TIM3_Init();
  MX_TIM4_Init();
  MX_TIM9_Init();
  MX_ADC3_Init();
//  MX_IWDG_Init();
  MX_TIM10_Init();
  MX_TIM5_Init();
  /* USER CODE BEGIN 2 */

  user_moter_power_ctr(1 );
  HAL_GPIO_WritePin(GPIOA, LOW_CTR1_Pin, GPIO_PIN_SET);//让Pmos不导通

	//CAN过滤配置、开启CAN外设
	CAN1_Filter_Init();
	CAN2_Filter_Init();
	CAN3_Filter_Init();

  user_uart_init( );
  user_ad_dma_init();
  user_PWM_init( );
  user_pend_switch_init( );
  YmodeCANUPGInit( );

	 user_data_init( );
	 User_Flash_Stor_Infor_Init( );
	 user_basic_infor_init( );

	 user_data_check();
	 turn_table_init();  //标定的秧版秧台数据初始化
	 show_infor( );

  /* USER CODE END 2 */

  /* Init scheduler */
  osKernelInitialize();  /* Call init function for freertos objects (in freertos.c) */
  MX_FREERTOS_Init();

  /* Start scheduler */
  osKernelStart();

  /* We should never get here as control is now taken by the scheduler */
  /* Infinite loop */
  while (1)
  {

  }
}

void SystemClock_Config(void)
{
  RCC_OscInitTypeDef RCC_OscInitStruct = {0};
  RCC_ClkInitTypeDef RCC_ClkInitStruct = {0};

  /** Configure the main internal regulator output voltage
  */
  __HAL_RCC_PWR_CLK_ENABLE();
  __HAL_PWR_VOLTAGESCALING_CONFIG(PWR_REGULATOR_VOLTAGE_SCALE3);

  /** Initializes the RCC Oscillators according to the specified parameters
  * in the RCC_OscInitTypeDef structure.
  */
  RCC_OscInitStruct.OscillatorType = RCC_OSCILLATORTYPE_LSI|RCC_OSCILLATORTYPE_HSE;
  RCC_OscInitStruct.HSEState = RCC_HSE_ON;
  RCC_OscInitStruct.LSIState = RCC_LSI_ON;
  RCC_OscInitStruct.PLL.PLLState = RCC_PLL_ON;
  RCC_OscInitStruct.PLL.PLLSource = RCC_PLLSOURCE_HSE;
  RCC_OscInitStruct.PLL.PLLM = 4;
  RCC_OscInitStruct.PLL.PLLN = 100;
  RCC_OscInitStruct.PLL.PLLP = RCC_PLLP_DIV2;
  RCC_OscInitStruct.PLL.PLLQ = 2;
  RCC_OscInitStruct.PLL.PLLR = 2;
  if (HAL_RCC_OscConfig(&RCC_OscInitStruct) != HAL_OK)
  {
    Error_Handler();
  }

  /** Activate the Over-Drive mode
  */
  if (HAL_PWREx_EnableOverDrive() != HAL_OK)
  {
    Error_Handler();
  }

  /** Initializes the CPU, AHB and APB buses clocks
  */
  RCC_ClkInitStruct.ClockType = RCC_CLOCKTYPE_HCLK|RCC_CLOCKTYPE_SYSCLK
                              |RCC_CLOCKTYPE_PCLK1|RCC_CLOCKTYPE_PCLK2;
  RCC_ClkInitStruct.SYSCLKSource = RCC_SYSCLKSOURCE_PLLCLK;
  RCC_ClkInitStruct.AHBCLKDivider = RCC_SYSCLK_DIV1;
  RCC_ClkInitStruct.APB1CLKDivider = RCC_HCLK_DIV2;
  RCC_ClkInitStruct.APB2CLKDivider = RCC_HCLK_DIV1;

  if (HAL_RCC_ClockConfig(&RCC_ClkInitStruct, FLASH_LATENCY_3) != HAL_OK)
  {
    Error_Handler();
  }
}

void HAL_TIM_PeriodElapsedCallback(TIM_HandleTypeDef *htim)
{
  if (htim->Instance == TIM14) {
    HAL_IncTick();
  }
}

void Error_Handler(void)
{
}

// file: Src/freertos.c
 /* USER CODE BEGIN Header */
/**
  ******************************************************************************
  * File Name          : freertos.c
  * Description        : Code for freertos applications
  ******************************************************************************
  * @attention
  *
  * <h2><center>&copy; Copyright (c) 2020 STMicroelectronics.
  * All rights reserved.</center></h2>
  *
  * This software component is licensed by ST under Ultimate Liberty license
  * SLA0044, the "License"; You may not use this file except in compliance with
  * the License. You may obtain a copy of the License at:
  *                             www.st.com/SLA0044
  *
  ******************************************************************************
  */
/* USER CODE END Header */

#include "FreeRTOS.h"
#include "task.h"
#include "main.h"
#include "cmsis_os.h"

/* USER CODE BEGIN Includes */
#include "USER_GLOBAL.h"
#include "stm32f7xx_hal_can.h"
#include "can.h"
#include "usart.h"
#include "tim.h"
#include "USER_FLASH.h"
#include "gpio.h"
#include "USER_PRO.h"
#include "stdio.h"
#include "string.h"
#include "USER_SET.h"
#include "dma.h"
#include "iwdg.h"
#include "USER_WIRE_LESS.h"
#include "USER_PPM.h"
#include "USER_PRO.h"
#include "USER_MISC.h"
#include "USER_MOTER.h"
#include "stdint.h"
#include "math.h"
/* USER CODE END Includes */

/* Definitions for defaultTask */
osThreadId_t defaultTaskHandle;
const osThreadAttr_t defaultTask_attributes = {
  .name = "defaultTask",
  .stack_size = 128 * 4,
  .priority = (osPriority_t) osPriorityLow,
};
/* Definitions for myTask02 */
osThreadId_t myTask02Handle;
const osThreadAttr_t myTask02_attributes = {
  .name = "myTask02",
  .stack_size = 128 * 4,
  .priority = (osPriority_t) osPriorityHigh7,
};
/* Definitions for myTask03 */
osThreadId_t myTask03Handle;
const osThreadAttr_t myTask03_attributes = {
  .name = "myTask03",
  .stack_size = 128 * 4,
  .priority = (osPriority_t) osPriorityHigh6,
};
/* Definitions for myTask04 */
osThreadId_t myTask04Handle;
const osThreadAttr_t myTask04_attributes = {
  .name = "myTask04",
  .stack_size = 128 * 4,
  .priority = (osPriority_t) osPriorityHigh5,
};
/* Definitions for myTask05 */
osThreadId_t myTask05Handle;
const osThreadAttr_t myTask05_attributes = {
  .name = "myTask05",
  .stack_size = 128 * 4,
  .priority = (osPriority_t) osPriorityHigh4,
};
/* Definitions for myTask06 */
osThreadId_t myTask06Handle;
const osThreadAttr_t myTask06_attributes = {
  .name = "myTask06",
  .stack_size = 128 * 4,
  .priority = (osPriority_t) osPriorityHigh3,
};
/* Definitions for myTask07 */
osThreadId_t myTask07Handle;
const osThreadAttr_t myTask07_attributes = {
  .name = "myTask07",
  .stack_size = 128 * 4,
  .priority = (osPriority_t) osPriorityHigh2,
};
/* Definitions for myTask08 */
osThreadId_t myTask08Handle;
const osThreadAttr_t myTask08_attributes = {
  .name = "myTask08",
  .stack_size = 128 * 4,
  .priority = (osPriority_t) osPriorityNormal7,
};
/* Definitions for myTask09 */
osThreadId_t myTask09Handle;
const osThreadAttr_t myTask09_attributes = {
  .name = "myTask09",
  .stack_size = 128 * 4,
  .priority = (osPriority_t) osPriorityNormal6,
};
/* Definitions for myTask10 */
osThreadId_t myTask10Handle;
const osThreadAttr_t myTask10_attributes = {
  .name = "myTask10",
  .stack_size = 128 * 4,
  .priority = (osPriority_t) osPriorityNormal5,
};
/* Definitions for myTask11 */
osThreadId_t myTask11Handle;
const osThreadAttr_t myTask11_attributes = {
  .name = "myTask11",
  .stack_size = 128 * 4,
  .priority = (osPriority_t) osPriorityNormal4,
};
/* Definitions for myTask12 */
osThreadId_t myTask12Handle;
const osThreadAttr_t myTask12_attributes = {
  .name = "myTask12",
  .stack_size = 128 * 4,
  .priority = (osPriority_t) osPriorityNormal3,
};
/* Definitions for myTask13 */
osThreadId_t myTask13Handle;
const osThreadAttr_t myTask13_attributes = {
  .name = "myTask13",
  .stack_size = 128 * 4,
  .priority = (osPriority_t) osPriorityNormal2,
};
/* Definitions for myTask14 */
osThreadId_t myTask14Handle;
const osThreadAttr_t myTask14_attributes = {
  .name = "myTask14",
  .stack_size = 128 * 4,
  .priority = (osPriority_t) osPriorityNormal1,
};
/* Definitions for myTask15 */
osThreadId_t myTask15Handle;
const osThreadAttr_t myTask15_attributes = {
  .name = "myTask15",
  .stack_size = 128 * 4,
  .priority = (osPriority_t) osPriorityNormal,
};
/* Definitions for myTask20 */
osThreadId_t myTask20Handle;
const osThreadAttr_t myTask20_attributes = {
  .name = "myTask20",
  .stack_size = 128 * 4,
  .priority = (osPriority_t) osPriorityLow1,
};
/* Definitions for myTask16 */
osThreadId_t myTask16Handle;
const osThreadAttr_t myTask16_attributes = {
  .name = "myTask16",
  .stack_size = 128 * 4,
  .priority = (osPriority_t) osPriorityBelowNormal7,
};
/* Definitions for myTask17 */
osThreadId_t myTask17Handle;
const osThreadAttr_t myTask17_attributes = {
  .name = "myTask17",
  .stack_size = 128 * 4,
  .priority = (osPriority_t) osPriorityBelowNormal6,
};
/* Definitions for myTask18 */
osThreadId_t myTask18Handle;
const osThreadAttr_t myTask18_attributes = {
  .name = "myTask18",
  .stack_size = 128 * 4,
  .priority = (osPriority_t) osPriorityBelowNormal5,
};
/* Definitions for myTask19 */
osThreadId_t myTask19Handle;
const osThreadAttr_t myTask19_attributes = {
  .name = "myTask19",
  .stack_size = 128 * 4,
  .priority = (osPriority_t) osPriorityBelowNormal4,
};
/* Definitions for myTask21 */
osThreadId_t myTask21Handle;
const osThreadAttr_t myTask21_attributes = {
  .name = "myTask21",
  .stack_size = 128 * 4,
  .priority = (osPriority_t) osPriorityRealtime1,
};
/* Definitions for myQueueCan2Rev */
osMessageQueueId_t myQueueCan2RevHandle;
const osMessageQueueAttr_t myQueueCan2Rev_attributes = {
  .name = "myQueueCan2Rev"
};
/* Definitions for myQueueCan1Rev */
osMessageQueueId_t myQueueCan1RevHandle;
const osMessageQueueAttr_t myQueueCan1Rev_attributes = {
  .name = "myQueueCan1Rev"
};
/* Definitions for myQueueCan3Rev */
osMessageQueueId_t myQueueCan3RevHandle;
const osMessageQueueAttr_t myQueueCan3Rev_attributes = {
  .name = "myQueueCan3Rev"
};
/* Definitions for myQueueUart7Rec */
osMessageQueueId_t myQueueUart7RecHandle;
const osMessageQueueAttr_t myQueueUart7Rec_attributes = {
  .name = "myQueueUart7Rec"
};
/* Definitions for myQueueUart2Spi3Rec */
osMessageQueueId_t myQueueUart2Spi3RecHandle;
const osMessageQueueAttr_t myQueueUart2Spi3Rec_attributes = {
  .name = "myQueueUart2Spi3Rec"
};

/* Definitions for myCountingSemMoter1 */
osSemaphoreId_t myCountingSemMoter1Handle;
const osSemaphoreAttr_t myCountingSemMoter1_attributes = {
  .name = "myCountingSemMoter1"
};
/* Definitions for myCountingSemMoter2 */
osSemaphoreId_t myCountingSemMoter2Handle;
const osSemaphoreAttr_t myCountingSemMoter2_attributes = {
  .name = "myCountingSemMoter2"
};
/* Definitions for myCountingSemMoter3 */
osSemaphoreId_t myCountingSemMoter3Handle;
const osSemaphoreAttr_t myCountingSemMoter3_attributes = {
  .name = "myCountingSemMoter3"
};
/* Definitions for myCountingSemMoter4 */
osSemaphoreId_t myCountingSemMoter4Handle;
const osSemaphoreAttr_t myCountingSemMoter4_attributes = {
  .name = "myCountingSemMoter4"
};
/* Definitions for myCountingSemMoter5 */
osSemaphoreId_t myCountingSemMoter5Handle;
const osSemaphoreAttr_t myCountingSemMoter5_attributes = {
  .name = "myCountingSemMoter5"
};
/* Definitions for myCountingSemEngine */
osSemaphoreId_t myCountingSemEngineHandle;
const osSemaphoreAttr_t myCountingSemEngine_attributes = {
  .name = "myCountingSemEngine"
};

/* Definitions for myCountingSemElecAccelerator */
osSemaphoreId_t myCountingSemElecAcceleratorHandle;
const osSemaphoreAttr_t myCountingSemElecAccelerator_attributes = {
  .name = "myCountingSemElecAccelerator"
};
/* Definitions for myCountingSemTube */
osSemaphoreId_t myCountingSemTubeHandle;
const osSemaphoreAttr_t myCountingSemTube_attributes = {
  .name = "myCountingSemTube"
};
/* Definitions for myCountingSemTurn */
osSemaphoreId_t myCountingSemTurnHandle;
const osSemaphoreAttr_t myCountingSemTurn_attributes = {
  .name = "myCountingSemTurn"
};
/* Definitions for myCountingSemAutoTurn */
osSemaphoreId_t myCountingSemAutoTurnHandle;
const osSemaphoreAttr_t myCountingSemAutoTurn_attributes = {
  .name = "myCountingSemAutoTurn"
};

void StartDefaultTask(void *argument);
void StartTask02(void *argument);
void StartTask03(void *argument);
void StartTask04(void *argument);
void StartTask05(void *argument);
void StartTask06(void *argument);
void StartTask07(void *argument);
void StartTask08(void *argument);
void StartTask09(void *argument);
void StartTask10(void *argument);
void StartTask11(void *argument);
void StartTask12(void *argument);
void StartTask13(void *argument);
void StartTask14(void *argument);
void StartTask15(void *argument);
void StartTask20(void *argument);
void StartTask16(void *argument);
void StartTask17(void *argument);
void StartTask18(void *argument);
void StartTask19(void *argument);
void StartTask21(void *argument);

void MX_FREERTOS_Init(void); /* (MISRA C 2004 rule 8.1) */

void MX_FREERTOS_Init(void) {

  /* Create the semaphores(s) */
  /* creation of myCountingSemMoter1 */
  myCountingSemMoter1Handle = osSemaphoreNew(1, 1, &myCountingSemMoter1_attributes);

  /* creation of myCountingSemMoter2 */
  myCountingSemMoter2Handle = osSemaphoreNew(1, 1, &myCountingSemMoter2_attributes);

  /* creation of myCountingSemMoter3 */
  myCountingSemMoter3Handle = osSemaphoreNew(1, 1, &myCountingSemMoter3_attributes);

  /* creation of myCountingSemMoter4 */
  myCountingSemMoter4Handle = osSemaphoreNew(1, 1, &myCountingSemMoter4_attributes);

  /* creation of myCountingSemMoter5 */
  myCountingSemMoter5Handle = osSemaphoreNew(1, 1, &myCountingSemMoter5_attributes);

  /* creation of myCountingSemEngine */
  myCountingSemEngineHandle = osSemaphoreNew(1, 1, &myCountingSemEngine_attributes);

  /* creation of myCountingSemPend1 */

  /* creation of myCountingSemElecAccelerator */
  myCountingSemElecAcceleratorHandle = osSemaphoreNew(1, 1, &myCountingSemElecAccelerator_attributes);

  /* creation of myCountingSemTube */
  myCountingSemTubeHandle = osSemaphoreNew(1, 1, &myCountingSemTube_attributes);

  /* creation of myCountingSemTurn */
  myCountingSemTurnHandle = osSemaphoreNew(1, 1, &myCountingSemTurn_attributes);

  /* creation of myCountingSemAutoTurn */
  myCountingSemAutoTurnHandle = osSemaphoreNew(1, 1, &myCountingSemAutoTurn_attributes);

  /* Create the queue(s) */
  /* creation of myQueueCan2Rev */
  myQueueCan2RevHandle = osMessageQueueNew (5, 12, &myQueueCan2Rev_attributes);

  /* creation of myQueueCan1Rev */
  myQueueCan1RevHandle = osMessageQueueNew (5, 12, &myQueueCan1Rev_attributes);

  /* creation of myQueueCan3Rev */
  myQueueCan3RevHandle = osMessageQueueNew (5, 12, &myQueueCan3Rev_attributes);

  /* creation of myQueueUart7Rec */
  myQueueUart7RecHandle = osMessageQueueNew (2, 30, &myQueueUart7Rec_attributes);

  /* creation of myQueueUart2Spi3Rec */
  myQueueUart2Spi3RecHandle = osMessageQueueNew (6, 10, &myQueueUart2Spi3Rec_attributes);

  /* Create the thread(s) */
  /* creation of defaultTask */
  defaultTaskHandle = osThreadNew(StartDefaultTask, NULL, &defaultTask_attributes);

  /* creation of myTask02 */
  myTask02Handle = osThreadNew(StartTask02, NULL, &myTask02_attributes);

  /* creation of myTask03 */
  myTask03Handle = osThreadNew(StartTask03, NULL, &myTask03_attributes);

  /* creation of myTask04 */
  myTask04Handle = osThreadNew(StartTask04, NULL, &myTask04_attributes);

  /* creation of myTask05 */
  myTask05Handle = osThreadNew(StartTask05, NULL, &myTask05_attributes);

  /* creation of myTask06 */
  myTask06Handle = osThreadNew(StartTask06, NULL, &myTask06_attributes);

  /* creation of myTask07 */
  myTask07Handle = osThreadNew(StartTask07, NULL, &myTask07_attributes);

  /* creation of myTask08 */
  myTask08Handle = osThreadNew(StartTask08, NULL, &myTask08_attributes);

  /* creation of myTask09 */
  myTask09Handle = osThreadNew(StartTask09, NULL, &myTask09_attributes);

  /* creation of myTask10 */
  myTask10Handle = osThreadNew(StartTask10, NULL, &myTask10_attributes);

  /* creation of myTask11 */
  myTask11Handle = osThreadNew(StartTask11, NULL, &myTask11_attributes);

  /* creation of myTask12 */
  myTask12Handle = osThreadNew(StartTask12, NULL, &myTask12_attributes);

  /* creation of myTask13 */
  myTask13Handle = osThreadNew(StartTask13, NULL, &myTask13_attributes);

  /* creation of myTask14 */
  myTask14Handle = osThreadNew(StartTask14, NULL, &myTask14_attributes);

  /* creation of myTask15 */
  myTask15Handle = osThreadNew(StartTask15, NULL, &myTask15_attributes);

  /* creation of myTask20 */
  myTask20Handle = osThreadNew(StartTask20, NULL, &myTask20_attributes);

  /* creation of myTask16 */
  myTask16Handle = osThreadNew(StartTask16, NULL, &myTask16_attributes);

  /* creation of myTask17 */
  myTask17Handle = osThreadNew(StartTask17, NULL, &myTask17_attributes);

  /* creation of myTask18 */
  myTask18Handle = osThreadNew(StartTask18, NULL, &myTask18_attributes);

  /* creation of myTask19 */
  myTask19Handle = osThreadNew(StartTask19, NULL, &myTask19_attributes);

  /* creation of myTask21 */
  myTask21Handle = osThreadNew(StartTask21, NULL, &myTask21_attributes);

}

void StartDefaultTask(void *argument)
{
  /* USER CODE BEGIN StartDefaultTask */
  /* Infinite loop */ //HH 没有使用到
	 HAL_GPIO_WritePin(GPIOG, REL_COM_Pin, GPIO_PIN_SET);//公共端12电接入驱动器
	 HAL_GPIO_WritePin(GPIOG,REL_ACC_Pin, GPIO_PIN_SET);//整车上电
	for(;;)
  {
    osDelay(1000);
  }
  /* USER CODE END StartDefaultTask */
}

/* USER CODE BEGIN Header_StartTask02 */
/**task2用于can和上位机通讯
* @brief Function implementing the myTask02 thread.
* @param argument: Not used
* @retval None
*/
/* USER CODE END Header_StartTask02 */
void StartTask02(void *argument)
{
  /* USER CODE BEGIN StartTask02 */
  /* Infinite loop */
//	uint8 msg[12]={0};
  osStatus_t status;
	HAL_GPIO_WritePin(GPIOG, CAN2_RSIS_Pin, GPIO_PIN_SET);//CAN2的终端电阻接上

  for(;;)
  {
		status = osMessageQueueGet(myQueueCan2RevHandle , j1939_msg_rev_can2.Array, NULL,0xffffffff);   // wait for message
		if (status == osOK)
		{
      uint8 i;
			uint16 pgn_temp ;
			pgn_temp=(uint16)j1939_msg_rev_can2.Array[1]<<8|j1939_msg_rev_can2.Array[2];

			for(i=0;i<FUNC_CAN2_MAX_NUM;i++)
			{
				if(user_can2_pro_func[i].pgn==pgn_temp)
				{
						user_can2_pro_func[i].pfun( &j1939_msg_rev_can2);
						break ;
				}
			}
//			user_rec_radio_data_flag =0x01;//表示收到信息
		}
    osDelay(1);
  }
  /* USER CODE END StartTask02 */
}

/* USER CODE BEGIN Header_StartTask03 */
/**task3用于本地无线数据接收
* @brief Function implementing the myTask03 thread.
* @param argument: Not used
* @retval None
*/
/* USER CODE END Header_StartTask03 */
void StartTask03(void *argument)
{
  /* USER CODE BEGIN StartTask03 */
			uint8 msg_uart2_Rx[24]={0};

		osStatus_t uart2_status;
	   user_wl_init(&user_wl_struct);//初始化为跳频模式

		if( user_wl_pra_RD(&user_wl_struct)==1)//读id，ch出错
		{
			user_send_str(&huart7,"无线模块参数读取失败");
		}
//		user_send_str(&huart7,"无线模块参数读取成功");

  /* Infinite loop */
  for(;;)
  {
		//这个队列仅用于触发
		uart2_status = osMessageQueueGet(myQueueUart2Spi3RecHandle , &msg_uart2_Rx, NULL, 0xffffffff);   // wait for message
		if (uart2_status == osOK)
		{
				user_wl_pro(&user_wl_struct);//处理无线数据，
				memset(msg_uart2_Rx,0x00,sizeof(msg_uart2_Rx));
		}
    osDelay(1);
  }
  /* USER CODE END StartTask03 */
}

/* USER CODE BEGIN Header_StartTask04 */
/**用于实时状态查询
* @brief Function implementing the myTask04 thread.
* @param argument: Not used
* @retval None
*/
/* USER CODE END Header_StartTask04 */
void StartTask04(void *argument)
{
  /* USER CODE BEGIN StartTask04 */
  /* Infinite loop */
	for(;;)
  {
		user_AD_val_get( );//
//		user_safe_ctr( );//安全限位
    HAL_IWDG_Refresh(&hiwdg);//喂狗
		osDelay(5);
  }
  /* USER CODE END StartTask04 */
}

/* USER CODE BEGIN Header_StartTask05 */
/**用于can传感器之类的数据处理和接收
* @brief Function implementing the myTask05 thread.
* @param argument: Not used
* @retval None
*/
/* USER CODE END Header_StartTask05 */
void StartTask05(void *argument)
{
  /* USER CODE BEGIN StartTask05 */
  /* Infinite loop */
  osStatus_t status;
	HAL_GPIO_WritePin(GPIOF, CAN1_RESIS_Pin, GPIO_PIN_SET);//CAN1的终端电阻接上
	for(;;)
  {
		status = osMessageQueueGet(myQueueCan1RevHandle , j1939_msg_rev_can1.Array , NULL, 0xffffffff);   // wait for message
		if (status == osOK)
		{
      uint8 i;
			uint16 pgn_temp ;
			pgn_temp=(uint16)j1939_msg_rev_can1.Array[1]<<8|j1939_msg_rev_can1.Array[2];

			for(i=0;i<FUNC_CAN1_MAX_NUM;i++)
			{
				if(user_can1_pro_func[i].pgn==pgn_temp)
				{
						user_can1_pro_func[i].pfun( &j1939_msg_rev_can1);
						break ;
				}
			}
			; // process data
    }
    osDelay(1);
  }
  /* USER CODE END StartTask05 */
}

void StartTask06(void *argument)
{
  /* USER CODE BEGIN StartTask06 */
  /* Infinite loop */
   uint8  speed_text[8] = {0xf0,0xe0,0x80,0x7d,0xff,0xff,0xff,0xff}; //停止
   int speed_temp2=0;
  for(;;)
  {
    if(speed_text1 == 1)//hh  本任务仅用于测试设置的基准速度，有无明显不合理;
    {
			//user_moter_pra.speed_init    hh  可以认为是一个比例系数，目前是-150*（17或者18），浮点数会更好？
      user_moter_pra.speed_base=(user_moter_pra.speed_init * YangTai_speed + 8032)*4; //基准速度，秧台速度，改task仅用于串口测试,

			if(user_moter_pra.speed_base < 100)
				user_moter_pra.speed_base = 100;

      speed_temp2 = user_moter_pra.speed_base;
			speed_text[2] =  speed_temp2 &0xff;
			speed_text[3] =  speed_temp2>>8;
			user_can_EXTID_send(&hcan2,0x0cff9826, speed_text, (uint32_t*)CAN_TX_MAILBOX0);
    }
    osDelay(50);
  }
  /* USER CODE END StartTask06 */
}

void StartTask07(void *argument)
{
  /* USER CODE BEGIN StartTask07 */
  /* Infinite loop */
	char msg_uart7_Rx[24]="0";
  osStatus_t status;
  for(;;)
  {
		status = osMessageQueueGet(myQueueUart7RecHandle, &msg_uart7_Rx, NULL, 0xffffffff);   // wait for message
		if (status == osOK)
		{
				if(user_state.test_opr_mode==0x01)//测试模式
				{
//					User_Pra_TEST(user_set_buff ) ;
				}
				else//参数设置模式
				{
					User_Pra_Set(msg_uart7_Rx);
				}
				memset(msg_uart7_Rx,0x00,sizeof(msg_uart7_Rx));
		}
    osDelay(1);
  }
  /* USER CODE END StartTask07 */
}

/* USER CODE BEGIN Header_StartTask08 */
/**
* @brief Function implementing the myTask08 thread.
* @param argument: Not used
* @retval None
*/
//
/* USER CODE END Header_StartTask08 */
void StartTask08(void *argument)
{
  /* USER CODE BEGIN StartTask08 */
  /* Infinite loop */
//  osStatus_t val;
 uint8  speed[8] = {0xf0,0xe0,0x80,0x7d,0xff,0xff,0xff,0xff}; //停止
 user_state.speed_cur = user_moter_pra.speed_base;
 user_state.fit_mode = 0x02; //刚上电给复位
  for(;;)
  {
//		val = osSemaphoreAcquire(myCountingSemMoter1Handle, 0xffffffff);
//		if (val== osOK)
		//3停止运行；1无人状态下，跟随；
    if(user_state.fit_mode==0x03 || user_state.stop_sta == 1)//停止运行，正处于推苗过程中或者遥控器急停
    {
       suidong_rec = 0;
       int speed_temp = 0x7D80;
			 speed[2] =  speed_temp &0xff;
			 speed[3] =  speed_temp>>8;
			 user_can_EXTID_send(&hcan2,0x0cff9826, speed, (uint32_t*)CAN_TX_MAILBOX0);
       Zhu_cont_data[0] = 0x03; //当前为复位状态
    }
		else if((user_state.fit_mode==0x01) && (user_state.manul_auto == 0x02))//无人时
		{
			int speed_temp=0;
      user_moter_pra.speed_base=(user_moter_pra.speed_init * YangTai_speed+8032)*4;  //基准速度
      if((user_state.rice1_state == 3 || user_state.rice2_state == 3 || user_state.rice3_state == 3) && user_state.YangXiang_high == 1) //子控有秧板放下了，但秧箱抬起来了，停止动作，防止撞了
      {
         int speed_temp = 0x7D80;
			   speed[2] =  speed_temp &0xff;
			   speed[3] =  speed_temp>>8;
			   user_can_EXTID_send(&hcan2,0x0cff9826, speed, (uint32_t*)CAN_TX_MAILBOX0);
         suidong_rec = 1;
      }
      else if((user_state.rice1_state == 3 || user_state.rice2_state == 3 || user_state.rice3_state == 3) && YangTai_speed == 0) //子控有秧板放下了，但秧台速度停了，缓速运行，hh一般是秧台已经抬起来了（除了传感器故障）
      {
         speed_temp = (user_moter_pra.speed_init * 1.8+8032)*4;
			   speed[2] =  speed_temp &0xff;
			   speed[3] =  speed_temp>>8;
				 user_can_EXTID_send(&hcan2,0x0cff9826, speed, (uint32_t*)CAN_TX_MAILBOX0);
         suidong_rec = 2;
      }
      else
      {
        //在边缘换向时候
		    if((user_state.ang_m_dirc ==0) || (user_state.ang_s_dirc ==0))  //方向不明，换向时传感器检测不到    hh方向切换的时候，速度保持
				{
          if(user_state.speed_cur == 0x7D80) //此时碰巧停止状态，给缓速
          {
             user_state.speed_cur = (-1000 + 8032)*4;
          }
           speed_temp = user_state.speed_cur;  //换向时候维持当前速度不变
					 speed[2] =  speed_temp &0xff;
					 speed[3] =  speed_temp>>8;
					 user_can_EXTID_send(&hcan2,0x0cff9826, speed, (uint32_t*)CAN_TX_MAILBOX0);
           suidong_rec = 3;
				}
        //同向运行
				else if((user_state.ang_m_dirc ==1) && (user_state.ang_s_dirc ==1))  //同时向左
				{
 				   int32 num = user_state.ang_s_num - user_state.ang_m_num; //秧板 - 秧台位置
					 if(num>=0) //秧板在后，追赶
					 {
							speed_temp = user_moter_pra.speed_base + user_moter_pra.speed_f[num]; //追赶速度+基准速度
							m_thrd( &speed_temp,user_moter_pra.speed_base);
              suidong_rec = 4;

							if(num > 20)
							speed_temp = 100;  //大偏差，直接高速追赶
					 }
           else if(num<0) //秧板在前，等待
           {
              num = 0-num;
							speed_temp = user_moter_pra.speed_base - user_moter_pra.speed_b[num]; //追赶速度+基准速度
							m_thrd( &speed_temp,user_moter_pra.speed_base);
              suidong_rec = 5;

					    if(num > 20)
						    speed_temp = 32128;  //大偏差，静止等待
           }
					 speed[2] =  speed_temp &0xff;
				   speed[3] =  speed_temp>>8;
				   user_can_EXTID_send(&hcan2,0x0cff9826, speed, (uint32_t*)CAN_TX_MAILBOX0);
				}
				else if((user_state.ang_m_dirc == 2) && (user_state.ang_s_dirc == 2)) //同时向右
				{
 				   int32 num = user_state.ang_s_num - user_state.ang_m_num;  //秧板 - 秧台位置
					 if(num>=0) //秧板在前，等待
				   {
							speed_temp =   user_moter_pra.speed_base - user_moter_pra.speed_b[num];
							m_thrd( &speed_temp,user_moter_pra.speed_base);
              suidong_rec = 5;

					    if(num > 20)
						    speed_temp = 32128;  //大偏差，静止等待
				   }
           else if(num<0) //秧板在后，追赶
           {
              num = 0-num;
							speed_temp =   user_moter_pra.speed_base + user_moter_pra.speed_f[num];
							m_thrd( &speed_temp,user_moter_pra.speed_base);
              suidong_rec = 4;

					    if(num > 20)
						    speed_temp = 100;  //大偏差，高速追赶
           }
					 speed[2] =  speed_temp &0xff;
					 speed[3] =  speed_temp>>8;
					 user_can_EXTID_send(&hcan2,0x0cff9826, speed, (uint32_t*)CAN_TX_MAILBOX0);
				}

        //反向运行，hh 以到边缘的距离左依据，秧板近就追
				else if((user_state.ang_m_dirc ==1) && (user_state.ang_s_dirc ==2)) //秧台朝左，秧板向右
				{
           uint8 dis_m = 0; //秧台到边缘距离
           uint8 dis_s = 0; //秧板到边缘距离
           uint8 num = 0;

           dis_m = user_state.ang_m_num - 0;   //秧台向左，所以 它 - 0
           dis_s = 59 - user_state.ang_s_num;  //秧板向右，所以 59 - 它

           if(dis_s < dis_m)  //秧板的距离比秧台小，追赶
           {
              num = (59 - user_state.ang_m_num) + (59 - user_state.ang_s_num);
							speed_temp =   user_moter_pra.speed_base + user_moter_pra.speed_f[num];
							m_thrd( &speed_temp,user_moter_pra.speed_base);
              suidong_rec = 4;

					    if(num > 20)
						    speed_temp = 100;  //大偏差，高速追赶
           }
           else   //秧板的距离比秧台大，等待
           {
             num = user_state.ang_m_num + user_state.ang_s_num;
						 speed_temp =   user_moter_pra.speed_base - user_moter_pra.speed_b[num];
						 m_thrd( &speed_temp,user_moter_pra.speed_base);
             suidong_rec = 5;

					   if(num > 20)
						   speed_temp = 32128;  //大偏差，静止等待
           }
					 speed[2] =  speed_temp &0xff;
				   speed[3] =  speed_temp>>8;
					 user_can_EXTID_send(&hcan2,0x0cff9826, speed, (uint32_t*)CAN_TX_MAILBOX0);
				}

				else if((user_state.ang_m_dirc ==2) && (user_state.ang_s_dirc ==1)) //秧台向右，秧板向左
				{
           uint8 dis_m = 0; //秧台到边缘距离
           uint8 dis_s = 0; //秧板到边缘距离
           uint8 num = 0;

           dis_m = 59 - user_state.ang_m_num;   //秧台向右，所以 59 - 它
           dis_s = user_state.ang_s_num - 0;    //秧板向左，所以 它 - 0

           if(dis_s < dis_m)  //秧板的距离比秧台小，追赶
           {
              num = user_state.ang_m_num + user_state.ang_s_num;
							speed_temp =   user_moter_pra.speed_base + user_moter_pra.speed_f[num];
							m_thrd( &speed_temp,user_moter_pra.speed_base);
              suidong_rec = 4;

					    if(num > 20)
						    speed_temp = 100;  //大偏差，高速追赶
           }
           else   //秧板的距离比秧台大，等待
           {
             num = (59 - user_state.ang_m_num) + (59 - user_state.ang_s_num);
						 speed_temp =   user_moter_pra.speed_base - user_moter_pra.speed_b[num];
						 m_thrd( &speed_temp,user_moter_pra.speed_base);
             suidong_rec = 5;

					   if(num > 20)
						   speed_temp = 32128;  //大偏差，静止等待
           }
					 speed[2] =  speed_temp &0xff;
				   speed[3] =  speed_temp>>8;
					 user_can_EXTID_send(&hcan2,0x0cff9826, speed, (uint32_t*)CAN_TX_MAILBOX0);
				}
      }
			user_state.speed_cur	= speed_temp;

      Zhu_cont_data[0] = 1; //正在同步
       if(abs(user_state.ang_m_num - user_state.ang_m_num) < 5) //已经同步上，可以放秧了
       {
           if(user_state.YangXiang_high == 1) //当前转弯，秧箱是抬升状态
              Zhu_cont_data[0] = 1; //正在同步中
           else
            Zhu_cont_data[0] = 2;  //秧板已同步
       }
     speed_show = speed_temp;
		}

		else if(user_state.fit_mode==0x02) //回位，回到加苗的位置  //hh 指的是，把苗推到秧板的上面，
		{
      suidong_rec = 0;
      if((user_moter_pra.AN_reset_data>4095)||(user_moter_pra.AN_reset_data<=100)) //标定有问题，不动作
      {
          ;
      }
      else
      {
				int speed_temp = (-1000 + 8032)*4;
				if((AD_CH_value[0] - user_moter_pra.AN_reset_data < 50) && (user_moter_pra.AN_reset_data - AD_CH_value[0] < 50)) //距离很小
				{
					 speed_temp = 0x7D80; //停下
					 Zhu_cont_data[0] = 0x03; //秧板已复位
				}
				else if((AD_CH_value[0] - user_moter_pra.AN_reset_data < 200) && (user_moter_pra.AN_reset_data - AD_CH_value[0] < 200))
				{
					 speed_temp = (-560 + 8032)*4;
					 Zhu_cont_data[0] = 0x04; //秧板复位中
				}
				else if((AD_CH_value[0] - user_moter_pra.AN_reset_data < 400) && (user_moter_pra.AN_reset_data - AD_CH_value[0] < 400))
				{
					 speed_temp = (-900 + 8032)*4;
					 Zhu_cont_data[0] = 0x04; //秧板复位中
				}
				else
				{
					 speed_temp = (-1200 + 8032)*4;
					 Zhu_cont_data[0] = 0x04; //秧板复位中
				}
					 speed[2] =  speed_temp &0xff;
					 speed[3] =  speed_temp>>8;
					 user_can_EXTID_send(&hcan2,0x0cff9826, speed, (uint32_t*)CAN_TX_MAILBOX0);
		  }
    }
    else if(user_state.fit_mode==0x00)//；hh在标定的时候，不给电机发数据
    {
       suidong_rec = 0;
    }

	  osDelay(30);
  }
  /* USER CODE END StartTask08 */
}

/* USER CODE BEGIN Header_StartTask09 */
/*
* @brief Function implementing the myTask09 thread.
* @param argument: Not used
* @retval None
*/
//
/* USER CODE END Header_StartTask09 */  //hh抬样箱
void StartTask09(void *argument)
{
  /* USER CODE BEGIN StartTask09 */
  /* Infinite loop */
   osStatus_t val;
  user_moter_stop(0x02);
	for(;;)
  {
		val = osSemaphoreAcquire(myCountingSemMoter2Handle, 0xffffffff);
		if (val== osOK)
		{
			if(user_state.stop_sta == 0)// hh 未按下急停按钮
			{
					uint8 i = 0;
					if((user_state.YangXiang_high == 1)||(user_state.less_yangxiang == 1)) //秧箱升起
					{
						 user_moter_forward(0x02,500); //电机伸长
						 while(AD_CH_value[1] < user_flash_moter_pra.AN_Val[1][1]-20) //长度还没伸到位，继续升
						 {
								i++;
								osDelay(50);
								if(i > 200) //最长10秒钟断电
								break;
						 }
						 user_moter_stop(0x02); //电机停止
					}
					else if((user_state.YangXiang_high == 2)||(user_state.less_yangxiang == 2)) //秧箱落下
					{
						 user_moter_backward(0x02,500); //电机缩短
						 while(AD_CH_value[1] > user_flash_moter_pra.AN_Val[1][0]+20) //还未缩到位
						 {
								i++;
								osDelay(50);
								if(i > 200) //最长10秒钟断电
								break;
						 }
						 user_moter_stop(0x02); //电机停止
					}
			}
			else
			  user_moter_stop(0x02);
		}
    osDelay(100);
  }
  /* USER CODE END StartTask09 */
}

/* USER CODE BEGIN Header_StartTask10 */
/**
* @brief Function implementing the myTask10 thread.
* @param argument: Not used
* @retval None
*/
//卸粮
/* USER CODE END Header_StartTask10 */
void StartTask10(void *argument)//hh抬样箱
{
  /* USER CODE BEGIN StartTask10 */
  /* Infinite loop */
   osStatus_t val;
  user_moter_stop(0x03);
	for(;;)
  {
		val = osSemaphoreAcquire(myCountingSemMoter3Handle, 0xffffffff);
		if (val== osOK)
		{
			if(user_state.stop_sta == 0)
			{
					uint8 i = 0;
					if((user_state.YangXiang_high == 1)||(user_state.less_yangxiang == 1)) //秧箱升起
					{
						 user_moter_forward(0x03,500); //电机伸长
						 while(AD_CH_value[2] < user_flash_moter_pra.AN_Val[2][1]-20) //长度还没伸到位，继续升
						 {
								i++;
								osDelay(50);
								if(i > 200) //最长10秒钟断电
								break;
						 }
						 user_moter_stop(0x03); //电机停止
					}
					else if((user_state.YangXiang_high == 2)||(user_state.less_yangxiang == 2)) //秧箱落下
					{
						 user_moter_backward(0x03,500); //电机伸长
						 while(AD_CH_value[2] > user_flash_moter_pra.AN_Val[2][0]+20) //还未缩到位
						 {
								i++;
								osDelay(50);
								if(i > 200) //最长10秒钟断电
								break;
						 }
						 user_moter_stop(0x03); //电机停止
					}
			}
			else
				 user_moter_stop(0x03);
		}
    osDelay(100);
  }
  /* USER CODE END StartTask10 */
}

/* USER CODE BEGIN Header_StartTask11 */
//脱谷
/* USER CODE END Header_StartTask11 */ //hh抬样箱
void StartTask11(void *argument)
{
  /* USER CODE BEGIN StartTask11 */
  /* Infinite loop */
   osStatus_t val;
  user_moter_stop(0x04);
	for(;;)
  {
		val = osSemaphoreAcquire(myCountingSemMoter4Handle, 0xffffffff);
		if (val== osOK)
		{
			if(user_state.stop_sta == 0)
			{
        uint8 i = 0;
        if((user_state.YangXiang_high == 1)||(user_state.less_yangxiang == 1))//秧箱升起
        {
           user_moter_forward(0x04,500); //电机伸长
           while(AD_CH_value[3] < user_flash_moter_pra.AN_Val[3][1]-20) //长度还没伸到位，继续升
           {
              i++;
              osDelay(50);
              if(i > 200) //最长10秒钟断电
              break;
           }
           user_moter_stop(0x04); //电机停止
        }
        else if((user_state.YangXiang_high == 2)||(user_state.less_yangxiang == 2)) //秧箱落下
        {
           user_moter_backward(0x04,500); //电机伸长
           while(AD_CH_value[3] > user_flash_moter_pra.AN_Val[3][0]+20) //还未缩到位
           {
              i++;
              osDelay(50);
              if(i > 200) //最长10秒钟断电
              break;
           }
           user_moter_stop(0x04); //电机停止
        }
			}
			else
			  user_moter_stop(0x04);
		}
    osDelay(100);
  }
  /* USER CODE END StartTask11 */
}

/* USER CODE BEGIN Header_StartTask12 */
/* USER CODE END Header_StartTask12 *///hh抬样箱
void StartTask12(void *argument)
{
  /* USER CODE BEGIN StartTask12 */
  /* Infinite loop */
   osStatus_t val;
  user_moter_stop(0x05);
	for(;;)
  {
		val = osSemaphoreAcquire(myCountingSemMoter5Handle, 0xffffffff);
		if (val== osOK)
		{
			if(user_state.stop_sta == 0)
			{
        uint8 i = 0;
        if((user_state.YangXiang_high == 1)||(user_state.less_yangxiang == 1)) //秧箱升起
        {
           user_moter_forward(0x05,500); //电机伸长
           while(AD_CH_value[4] < user_flash_moter_pra.AN_Val[4][1]-20) //长度还没伸到位，继续升
           {
              i++;
              osDelay(50);
              if(i > 200) //最长10秒钟断电
              break;
           }
           user_moter_stop(0x05); //电机停止
        }
        else if((user_state.YangXiang_high == 2)||(user_state.less_yangxiang == 2)) //秧箱落下
        {
           user_moter_backward(0x05,500); //电机伸长
           while(AD_CH_value[4] > user_flash_moter_pra.AN_Val[4][0]+20) //还未缩到位
           {
              i++;
              osDelay(50);
              if(i > 200) //最长10秒钟断电
              break;
           }
           user_moter_stop(0x05); //电机停止
        }
			}
			else
				user_moter_stop(0x05);
		}
    osDelay(100);
  }
  /* USER CODE END StartTask12 */
}

/* USER CODE BEGIN Header_StartTask13 */
/**
* @brief Function implementing the myb thread.
* @param argument: Not used
* @retval None
*/
//hh 告诉无人控制器，原车的秧台是不是可以抬升
/* USER CODE END Header_StartTask13 */
void StartTask13(void *argument)
{
  /* USER CODE BEGIN StartTask13 */
  /* Infinite loop */
//   osStatus_t val;
	uint8 can_tx_high[8] = {0xff,0xff,0xff,0xff,0xff,0xff,0xff,0xff};
	for(;;)
  {
//		val = osSemaphoreAcquire(myCountingSemDOHandle, 0xffffffff);
//		if (val== osOK)
//		{
//
//    }
      if((AD_CH_value[1] > user_flash_moter_pra.AN_Val[1][1] - 100)&&
         (AD_CH_value[2] > user_flash_moter_pra.AN_Val[2][1] - 100)&&
         (AD_CH_value[3] > user_flash_moter_pra.AN_Val[3][1] - 100)&&
         (AD_CH_value[4] > user_flash_moter_pra.AN_Val[4][1] - 100))
      {
         can_tx_high[0] = 0x01;  //每个电机都抬到位，可以升 hh告诉无人控制器状态
      }
      else //禁止升
      {
         can_tx_high[0] = 0x02;
      }

      if(user_state.rice1_state == 3 || user_state.rice2_state == 3 || user_state.rice3_state == 3) //只要有秧板放下的，秧台禁止升
      {
         can_tx_high[0] = 0x02;
      }
      user_can_EXTID_send(&hcan2,0x0C900502,can_tx_high, (uint32_t*)CAN_TX_MAILBOX0); //告诉无人驾驶控制器，秧台能不能升
			osDelay(100);
	}
  /* USER CODE END StartTask13 */
}

/* USER CODE BEGIN Header_StartTask14 */
/**
* @brief Function implementing the myTask13 thread.
* @param argument: Not used
* @retval None
*/
//无阻塞 DO 查询方式，割台升降；5,1高位；5,0，低位
/* USER CODE END Header_StartTask14 */
void StartTask14(void *argument)
{
  /* USER CODE BEGIN StartTask14 */
  /* Infinite loop */

//	osStatus_t val;
	for(;;)//hh 子控制器上报单双列状态，主控反馈锁定的单双列给到所有子控制器
  {
//			val = osSemaphoreAcquire( myCountingSemPend1Handle, 0xffffffff);
//			if (val== osOK)
//			{

//      }
		if(user_state.stop_sta == 1) //急停，断电 hh断子控制器的电
		{
      HAL_GPIO_WritePin(GPIOE, DO4_Pin, GPIO_PIN_RESET);

		}
		else
			HAL_GPIO_WritePin(GPIOE, DO4_Pin, GPIO_PIN_SET);

    if(user_state.manul_auto == 2 && user_state.stop_sta == 0) //无人状态
    {
			 Zhu_cont_data[7] = user_state.lieshu_jilu;  //获取主控锁定状态，发给子控

       user_can_EXTID_send(&hcan1,0x0C900501, Zhu_cont_data, (uint32_t*)CAN_TX_MAILBOX0);	  //子控接CAN1,告知秧板状态
    }
    else if(user_state.manul_auto == 1) //手动状态才发 hh 遥控信息
    {
       user_can_EXTID_send(&hcan1,0x0C900601, Zhu_less_data, (uint32_t*)CAN_TX_MAILBOX0);	  //上苗装置遥控执行
			Zhu_less_data[7] = 0;
    }
		osDelay(100); //时间不可随意改
  }
  /* USER CODE END StartTask14 */
}

/* USER CODE BEGIN Header_StartTask15 */
/**
* @brief Function implementing the myTask15 thread.
* @param argument: Not used
* @retval None
*/
//hh 解析子控制器数据，设置跟随电机、单双列电机状态
/* USER CODE END Header_StartTask15 */
void StartTask15(void *argument)
{
  /* USER CODE BEGIN StartTask15 */
  /* Infinite loop */
//   osStatus_t val;

	uint8 i = 0;
	for(;;)
  {
//		val = osSemaphoreAcquire(myCountingSemEngineHandle, 0xffffffff);
//		if (val== osOK)
//		{
//
//		}
		//相同的列在推苗，有新的需要推，就一起推。后续一起加。
    if(user_state.rice1_state == 2 || user_state.rice2_state == 2 || user_state.rice3_state == 2) //只要有一个在推苗中，就保持不动
    {
       i = 1;
       user_state.fit_mode = 3;
    }
    else if(user_state.rice1_state == 1 || user_state.rice2_state == 1 || user_state.rice3_state == 1) //没有正在推苗，只要有一个推苗完成就开始同步
    {
			 i = 1;
       user_state.fit_mode = 1; //秧板同步
			 user_state.huanhang_sta = user_state.lieshu_jilu; //hh 同步时，考虑单双列，和同步电机，同时进行
			 osSemaphoreRelease(myCountingSemElecAcceleratorHandle); //样板换行操作
    }
    else if(user_state.rice1_state != 3 && user_state.rice2_state != 3 && user_state.rice3_state != 3) //没有正在卸苗的
    {
       if(user_state.rice1_state == 4 || user_state.rice2_state == 4 || user_state.rice3_state == 4) //并且有已经卸苗完成的
       {
				 if(i == 1)
				 {
					 i = 0;
					 user_state.lieshu_jilu = 0;   //列数标记清除
				 }

         user_state.fit_mode = 2;      //随动复位
				 user_state.huanhang_sta = 0;  //换列电机复位
				 osSemaphoreRelease(myCountingSemElecAcceleratorHandle); //换行执行复位
       }
    }
    osDelay(10);
  }
  /* USER CODE END StartTask15 */
}

void StartTask20(void *argument)
{
  /* USER CODE BEGIN StartTask20 */
  /* Infinite loop */

  user_state.manul_auto = 0x01;//初始默认是人工操作
	for(;;)
  {
    osDelay(100);
  }
  /* USER CODE END StartTask20 */
}

/* USER CODE BEGIN Header_StartTask16 */
/**
* @brief Function implementing the myTask16 thread.
* @param argument: Not used
* @retval None
*/
//hh 判断样板、秧台运动方向和位置
/* USER CODE END Header_StartTask16 */
void StartTask16(void *argument)
{
  /* USER CODE BEGIN StartTask16 */
  /* Infinite loop */
	static int  AD_CH_value6_temp;
	static int  AD_CH_value6_record1,AD_CH_value6_record2,AD_CH_value6_record3,AD_CH_value6_record4,AD_CH_value6_record5;

	static int  AD_CH_value0_temp;
	static int  AD_CH_value0_record1,AD_CH_value0_record2,AD_CH_value0_record3,AD_CH_value0_record4,AD_CH_value0_record5;

	static uint8 m_data = 0;  //秧台  1左侧AD值大；2侧AD值大
	static uint8 m_l_r = 0;   //秧台  1向左移动；2向右移动

	static uint8 s_data = 0; //1左大；2右大
	static uint8 s_l_r = 0;   //1左方向；2右方向

	uint8 ang_s_num =0;  //秧板所在位置
 	uint8 ang_m_num =0;  //秧台所在位置

	uint8 a0_thd =5;
	uint8 a6_thd =5;

	if( user_moter_pra.ang_m[0]>user_moter_pra.ang_m[59])//秧台，坐在驾驶位置，左侧大
	{
     m_data = 1;
	}
	else if( user_moter_pra.ang_m[0]<user_moter_pra.ang_m[59])//秧台，坐在驾驶位置，右侧大
	{
	   m_data = 2;
	}

	if( user_moter_pra.ang_s[0]>user_moter_pra.ang_s[59])//秧板，坐在驾驶位置，左侧大
	{
     s_data = 1;
	}
	else if( user_moter_pra.ang_s[0]<user_moter_pra.ang_s[59])//秧板，坐在驾驶位置，右侧大
	{
	   s_data = 2;
	}

	user_state.manul_auto = 0x01;//初始默认是人工操作
	for(;;)
  {
     AD_CH_value6_temp = AD_CH_value[6];//秧台获取数据,判断运动方向
     AD_CH_value0_temp = AD_CH_value[0];//秧板电机获取数据,判断运动方向

		if(AD_CH_value6_temp > (AD_CH_value6_record1 + a6_thd) && (AD_CH_value6_record1>AD_CH_value6_record2) + a6_thd) //AD值逐渐增大
		{
		  if(m_data==1) //左侧大，秧台向左移动
			  m_l_r = 1;
			else if(m_data==2) //右侧大，秧台向右移动
			  m_l_r = 2;
		}
		else if(AD_CH_value6_temp < (AD_CH_value6_record1 - a6_thd) && AD_CH_value6_record1 < (AD_CH_value6_record2 - a6_thd)) //AD值逐渐减小
		{
		  if(m_data==1) //左侧大，秧台向右移动
			  m_l_r = 2;
			else if(m_data==2) //右侧大，秧台向左移动
			  m_l_r = 1;
		}
		else//静止不动作
			 m_l_r = 0;

		if(AD_CH_value6_temp < user_moter_pra.ang_m[0]+60 || AD_CH_value6_temp > user_moter_pra.ang_m[59]-60)  //在边缘位置(目前确认AD值左侧小右侧大)
		  m_l_r = 0;

//		if( user_state.fit_mode!=0x01)//秧板不动作
//		  s_l_r = 0;
	  if(AD_CH_value0_temp > (AD_CH_value0_record1+  a0_thd) && AD_CH_value0_record1 > (AD_CH_value0_record2+ a0_thd)) //AD值逐渐变大
		{
		  if(s_data==1)//左侧大
			  s_l_r = 1;
			else if(s_data==2)//右侧大
			  s_l_r = 2;
		}
		else if(AD_CH_value0_temp < (AD_CH_value0_record1- a0_thd) && AD_CH_value0_record1 <(AD_CH_value0_record2-a0_thd)) //AD值逐渐减小
		{
		  if(s_data==1)//左侧大
			  s_l_r = 2;
			else if(s_data==2)//右侧大
			  s_l_r = 1;
		}
		else//静止不动作
			 s_l_r = 0;

		if(AD_CH_value0_temp < user_moter_pra.ang_s[0]+60 || AD_CH_value0_temp > user_moter_pra.ang_s[59]-60)  //在边缘位置(目前确认AD值左侧小右侧大)
		   s_l_r = 0;

		//判断秧台当前位置
		{
			uint8 i=0;
			for(i=0;i<60;i++)
			{
				if(AD_CH_value6_temp<user_moter_pra.ang_m[i])
				{
					 ang_m_num = i;
					 break;
				}
			}
		}

    //判断秧板当前位置
		{
			uint8 i=0;
			for(i=0;i<60;i++)
			{
				if(AD_CH_value0_temp<user_moter_pra.ang_s[i])
				{
					ang_s_num = i;
					break;
				}
			}
		}

		AD_CH_value6_record5 =AD_CH_value6_record4;
		AD_CH_value6_record4 =AD_CH_value6_record3;
		AD_CH_value6_record3 =AD_CH_value6_record2;
		AD_CH_value6_record2 =AD_CH_value6_record1;
//		AD_CH_value6_record1 =AD_CH_value[6];
    AD_CH_value6_record1 = AD_CH_value6_temp;

    AD_CH_value0_record5 =AD_CH_value0_record4;
		AD_CH_value0_record4 =AD_CH_value0_record3;
		AD_CH_value0_record3=AD_CH_value0_record2;
		AD_CH_value0_record2=AD_CH_value0_record1;
//		AD_CH_value0_record1 =AD_CH_value[0];
    AD_CH_value0_record1 = AD_CH_value0_temp;

		user_state.ang_m_dirc = m_l_r;	//秧台运行方向
		user_state.ang_s_dirc = s_l_r;  //秧板运行方向

	  user_state.ang_m_num = ang_m_num;	//秧台所处位置
	  user_state.ang_s_num = ang_s_num; //秧板所处位置

     //调试模式手动输，正式版屏蔽
//		user_state.ang_m_dirc = yangtai_dir;	//秧台运行方向
//		user_state.ang_s_dirc = yangban_dir;  //秧板运行方向
//
//	  user_state.ang_m_num = yangtai_wz;	//秧台所处位置
//	  user_state.ang_s_num = yangban_wz; //秧板所处位置

		osDelay(80);//要延时100ms，监测的是5个数据，500毫秒内的动作
  }
  /* USER CODE END StartTask16 */
}

/* USER CODE BEGIN Header_StartTask17 */
/* USER CODE END Header_StartTask17 */ //hh 换单双行，只有一个换行电机，最短最长分别对应单双行，复位在中间需要检测模拟量
void StartTask17(void *argument)
{
  /* USER CODE BEGIN StartTask17 */
  /* Infinite loop */
   osStatus_t val17;
	user_state.huanhang_sta = 0;
	osSemaphoreRelease(myCountingSemElecAcceleratorHandle);  //上电给复位
	for(;;)
  {
		val17 = osSemaphoreAcquire(myCountingSemElecAcceleratorHandle, 0xffffffff);
		if (val17== osOK)
		{
			 if(user_state.huanhang_sta == 0)  //复位
			 {
					 if(user_moter_pra.yangban_xuanzhe < 200 || user_moter_pra.yangban_xuanzhe > 4000) //标定错误，不动
					 {
						 user_moter_stop(0x01);
					 }
					 else if(AD_CH_value[5] > user_moter_pra.yangban_xuanzhe + 40)  //当前值大于复位值，缩短
					 {
						  uint16 num=0; //hh 后来添加

							while(AD_CH_value[5] > user_moter_pra.yangban_xuanzhe)
							{
								if(AD_CH_value[5] < (user_moter_pra.yangban_xuanzhe + 180))//大于100以内，低速
									user_moter_backward(0x01,180);
								else if(AD_CH_value[5] < (user_moter1.target_value + 300))//中速
									user_moter_backward(0x01,300);
								else
								user_moter_backward(0x01,500);

								{ //hh 后来添加
									num++;
                  osDelay(10);
									if(num>50)
									{
                     break;
									}
                }
								// osDelay(10);
							}
					 }
					 else if(AD_CH_value[5] < user_moter_pra.yangban_xuanzhe - 40) //当前值大于复位值，伸长
					 {
						  uint16 num=0; //hh 后来添加
							while(AD_CH_value[5] < user_moter_pra.yangban_xuanzhe)
							{
								if(AD_CH_value[5] > (user_moter_pra.yangban_xuanzhe - 180))
									user_moter_forward(0x01,180);
								else if(AD_CH_value[5] > (user_moter_pra.yangban_xuanzhe - 300))
									user_moter_forward(0x01,300);
								else
									user_moter_forward(0x01,500);

								{ //hh 后来添加
									num++;
                  osDelay(10);
									if(num>50)
									{
                     break;
									}
                }
								// osDelay(10);
							}
					 }
					 else //已经是复位状态
					 {
//							Zhu_cont_data[1] = 0;
					 }
		     user_moter_stop(0x01);
			 }
			 else if(user_state.huanhang_sta == 1)  //单列，缩短
			 {
				  user_moter_backward(0x01,500);
			 }
			 else if(user_state.huanhang_sta == 2) //双列，伸长
			 {
				  user_moter_forward(0x01,500);
			 }
		}
    osDelay(10);
  }
  /* USER CODE END StartTask17 */
}

void StartTask18(void *argument)
{
  /* USER CODE BEGIN StartTask18 */
  /* Infinite loop */
  char Ptr[30]={0};
	for(;;)//hh 串口调试用
  {
//     if(user_state.lieshu_jilu == 1)
//		 {
//
//		 }
		 if(user_state.manul_auto == 0x02)
		 {
			 user_send_str(&huart7, " ->随动模式，状态,速度：");
			 sprintf(Ptr,"%d,%d,%d\r\n",user_state.fit_mode,suidong_rec,speed_show);
			 user_send_str(&huart7, Ptr);
			 memset(Ptr,0,30);

			 user_send_str(&huart7, " ->列数选择：");
			 sprintf(Ptr,"%d\r\n",user_state.lieshu_jilu);
			 user_send_str(&huart7, Ptr);
			 memset(Ptr,0,30);

			 user_send_str(&huart7, " ->秧台方向，位置：");
			 sprintf(Ptr,"%d,%d\r\n",user_state.ang_m_dirc,user_state.ang_m_num);
			 user_send_str(&huart7, Ptr);
			 memset(Ptr,0,30);
			 user_send_str(&huart7, " ->秧板方向，位置：");
			 sprintf(Ptr,"%d,%d\r\n",user_state.ang_s_dirc,user_state.ang_s_num);
			 user_send_str(&huart7, Ptr);
			 memset(Ptr,0,30);
			 user_send_str(&huart7, " ->秧台速度：");
			 sprintf(Ptr,"%d\r\n",YangTai_speed);
			 user_send_str(&huart7, Ptr);
			 memset(Ptr,0,30);
		 }

		 if(speed_text1 == 2)
		 {
			 user_send_str(&huart7, " ->秧台速度：");
			 sprintf(Ptr,"%d\r\n",YangTai_speed);
			 user_send_str(&huart7, Ptr);
			 memset(Ptr,0,30);
		 }

		 HAL_GPIO_TogglePin(GPIOC, GPIO_PIN_7);		//灯闪
		 osDelay(500);
  }
  /* USER CODE END StartTask18 */
}

/* USER CODE BEGIN Header_StartTask19 */
/**
* @brief Function implementing the myTask19 thread.
* @param argument: Not used
* @retval None
*/
//粮筒的控制
/* USER CODE END Header_StartTask19 */
void StartTask19(void *argument)
{
  /* USER CODE BEGIN StartTask19 *///hh 样箱电机保护，不倾斜太多
  /* Infinite loop */
// 	osStatus_t val19;

	for(;;)
  {
     if(user_state.manul_auto == 0x02)
     {
        if( abs(AD_CH_value[1] - AD_CH_value[2]) > 600 ||
            abs(AD_CH_value[1] - AD_CH_value[3]) > 600 ||
            abs(AD_CH_value[1] - AD_CH_value[4]) > 600  )  //秧箱电机位置误差过大，停止
        {
           user_state.fit_mode = 0x03;

           user_moter_stop(0x02);
           user_moter_stop(0x03);
           user_moter_stop(0x04);
           user_moter_stop(0x05);
        }
     }
     osDelay(100);
  }
  /* USER CODE END StartTask19 */
}

/* USER CODE BEGIN Header_StartTask21 */
/**
* @brief Function implementing the myTask21 thread.
* @param argument: Not used
* @retval None
*/
//收割机转向
/* USER CODE END Header_StartTask21 */
void StartTask21(void *argument)
{
  /* USER CODE BEGIN StartTask21 */
  /* Infinite loop */
//  osStatus_t val21;
//  char Ptr[30]={0};

	uint8 wz1_rec = 0;
	uint8 wz2_rec = 0;
	YangTai_speed = 0;
	for(;;)
  {
//		val21 = osSemaphoreAcquire( myCountingSemAutoTurnHandle, 0xffffffff);
//		if(val21==osOK)
//		{
		//hh 检测秧台的左右速度,限定了特定区段来检测
      if(user_state.ang_m_dirc == 2 && user_state.ang_m_num>10 && user_state.ang_m_num<15) //秧板方向朝右
			{
			   wz1_rec = user_state.ang_m_num;
				 osDelay(1300);
				 wz2_rec = user_state.ang_m_num; //1.5秒后数据记录，看差值，越大速度越快
				 if(wz2_rec > 55)
					 wz2_rec = 55;

				 YangTai_speed = wz2_rec - wz1_rec;
			}

      osDelay(10);
//    }
  }
  /* USER CODE END StartTask21 */
}
